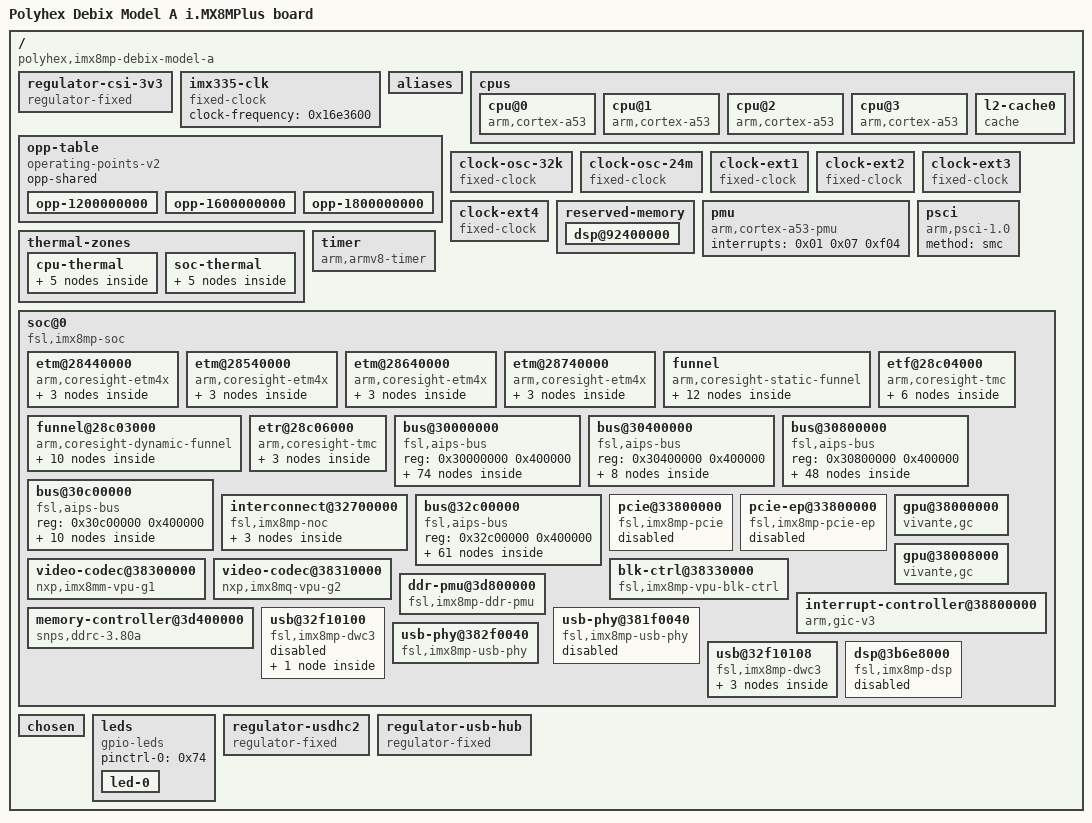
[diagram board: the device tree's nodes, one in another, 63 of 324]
/dts-v1/;

/ {
	interrupt-parent = <0x01>;
	#address-cells = <0x02>;
	#size-cells = <0x02>;
	model = "Polyhex Debix Model A i.MX8MPlus board";
	compatible = "polyhex,imx8mp-debix-model-a\0polyhex,imx8mp-debix\0fsl,imx8mp";

	regulator-csi-3v3 {
		phandle = <0xe7>;
		enable-active-high;
		gpio = <0x2f 0x06 0x00>;
		startup-delay-us = <0xc350>;
		regulator-min-microvolt = <0x325aa0>;
		regulator-max-microvolt = <0x325aa0>;
		regulator-name = "CSI_3V3";
		pinctrl-0 = <0xe3 0xe4>;
		pinctrl-names = "default";
		compatible = "regulator-fixed";
	};

	imx335-clk {
		phandle = <0xe6>;
		clock-frequency = <0x16e3600>;
		#clock-cells = <0x00>;
		compatible = "fixed-clock";
	};

	aliases {
		ethernet0 = "/soc@0/bus@30800000/ethernet@30be0000";
		ethernet1 = "/soc@0/bus@30800000/ethernet@30bf0000";
		gpio0 = "/soc@0/bus@30000000/gpio@30200000";
		gpio1 = "/soc@0/bus@30000000/gpio@30210000";
		gpio2 = "/soc@0/bus@30000000/gpio@30220000";
		gpio3 = "/soc@0/bus@30000000/gpio@30230000";
		gpio4 = "/soc@0/bus@30000000/gpio@30240000";
		i2c0 = "/soc@0/bus@30800000/i2c@30a20000";
		i2c1 = "/soc@0/bus@30800000/i2c@30a30000";
		i2c2 = "/soc@0/bus@30800000/i2c@30a40000";
		i2c3 = "/soc@0/bus@30800000/i2c@30a50000";
		i2c4 = "/soc@0/bus@30800000/i2c@30ad0000";
		i2c5 = "/soc@0/bus@30800000/i2c@30ae0000";
		mmc0 = "/soc@0/bus@30800000/mmc@30b40000";
		mmc1 = "/soc@0/bus@30800000/mmc@30b50000";
		mmc2 = "/soc@0/bus@30800000/mmc@30b60000";
		serial0 = "/soc@0/bus@30800000/spba-bus@30800000/serial@30860000";
		serial1 = "/soc@0/bus@30800000/spba-bus@30800000/serial@30890000";
		serial2 = "/soc@0/bus@30800000/spba-bus@30800000/serial@30880000";
		serial3 = "/soc@0/bus@30800000/serial@30a60000";
		spi0 = "/soc@0/bus@30800000/spi@30bb0000";
	};

	cpus {
		#address-cells = <0x01>;
		#size-cells = <0x00>;

		cpu@0 {
			device_type = "cpu";
			compatible = "arm,cortex-a53";
			reg = <0x00>;
			clock-latency = <0xee6c>;
			clocks = <0x02 0x11f>;
			enable-method = "psci";
			i-cache-size = <0x8000>;
			i-cache-line-size = <0x40>;
			i-cache-sets = <0x100>;
			d-cache-size = <0x8000>;
			d-cache-line-size = <0x40>;
			d-cache-sets = <0x80>;
			next-level-cache = <0x03>;
			nvmem-cells = <0x04>;
			nvmem-cell-names = "speed_grade";
			operating-points-v2 = <0x05>;
			#cooling-cells = <0x02>;
			cpu-supply = <0x06>;
			phandle = <0x09>;
		};

		cpu@1 {
			device_type = "cpu";
			compatible = "arm,cortex-a53";
			reg = <0x01>;
			clock-latency = <0xee6c>;
			clocks = <0x02 0x11f>;
			enable-method = "psci";
			i-cache-size = <0x8000>;
			i-cache-line-size = <0x40>;
			i-cache-sets = <0x100>;
			d-cache-size = <0x8000>;
			d-cache-line-size = <0x40>;
			d-cache-sets = <0x80>;
			next-level-cache = <0x03>;
			operating-points-v2 = <0x05>;
			#cooling-cells = <0x02>;
			cpu-supply = <0x06>;
			phandle = <0x0a>;
		};

		cpu@2 {
			device_type = "cpu";
			compatible = "arm,cortex-a53";
			reg = <0x02>;
			clock-latency = <0xee6c>;
			clocks = <0x02 0x11f>;
			enable-method = "psci";
			i-cache-size = <0x8000>;
			i-cache-line-size = <0x40>;
			i-cache-sets = <0x100>;
			d-cache-size = <0x8000>;
			d-cache-line-size = <0x40>;
			d-cache-sets = <0x80>;
			next-level-cache = <0x03>;
			operating-points-v2 = <0x05>;
			#cooling-cells = <0x02>;
			cpu-supply = <0x06>;
			phandle = <0x0b>;
		};

		cpu@3 {
			device_type = "cpu";
			compatible = "arm,cortex-a53";
			reg = <0x03>;
			clock-latency = <0xee6c>;
			clocks = <0x02 0x11f>;
			enable-method = "psci";
			i-cache-size = <0x8000>;
			i-cache-line-size = <0x40>;
			i-cache-sets = <0x100>;
			d-cache-size = <0x8000>;
			d-cache-line-size = <0x40>;
			d-cache-sets = <0x80>;
			next-level-cache = <0x03>;
			operating-points-v2 = <0x05>;
			#cooling-cells = <0x02>;
			cpu-supply = <0x06>;
			phandle = <0x0c>;
		};

		l2-cache0 {
			compatible = "cache";
			cache-unified;
			cache-level = <0x02>;
			cache-size = <0x80000>;
			cache-line-size = <0x40>;
			cache-sets = <0x200>;
			phandle = <0x03>;
		};
	};

	opp-table {
		compatible = "operating-points-v2";
		opp-shared;
		phandle = <0x05>;

		opp-1200000000 {
			opp-hz = <0x00 0x47868c00>;
			opp-microvolt = <0xcf850>;
			opp-supported-hw = <0x8a0 0x07>;
			clock-latency-ns = <0x249f0>;
			opp-suspend;
		};

		opp-1600000000 {
			opp-hz = <0x00 0x5f5e1000>;
			opp-microvolt = <0xe7ef0>;
			opp-supported-hw = <0xa0 0x07>;
			clock-latency-ns = <0x249f0>;
			opp-suspend;
		};

		opp-1800000000 {
			opp-hz = <0x00 0x6b49d200>;
			opp-microvolt = <0xf4240>;
			opp-supported-hw = <0x20 0x03>;
			clock-latency-ns = <0x249f0>;
			opp-suspend;
		};
	};

	clock-osc-32k {
		compatible = "fixed-clock";
		#clock-cells = <0x00>;
		clock-frequency = <0x8000>;
		clock-output-names = "osc_32k";
		phandle = <0x21>;
	};

	clock-osc-24m {
		compatible = "fixed-clock";
		#clock-cells = <0x00>;
		clock-frequency = <0x16e3600>;
		clock-output-names = "osc_24m";
		phandle = <0x22>;
	};

	clock-ext1 {
		compatible = "fixed-clock";
		#clock-cells = <0x00>;
		clock-frequency = <0x7ed6b40>;
		clock-output-names = "clk_ext1";
		phandle = <0x23>;
	};

	clock-ext2 {
		compatible = "fixed-clock";
		#clock-cells = <0x00>;
		clock-frequency = <0x7ed6b40>;
		clock-output-names = "clk_ext2";
		phandle = <0x24>;
	};

	clock-ext3 {
		compatible = "fixed-clock";
		#clock-cells = <0x00>;
		clock-frequency = <0x7ed6b40>;
		clock-output-names = "clk_ext3";
		phandle = <0x25>;
	};

	clock-ext4 {
		compatible = "fixed-clock";
		#clock-cells = <0x00>;
		clock-frequency = <0x7ed6b40>;
		clock-output-names = "clk_ext4";
		phandle = <0x26>;
	};

	reserved-memory {
		#address-cells = <0x02>;
		#size-cells = <0x02>;
		ranges;

		dsp@92400000 {
			reg = <0x00 0x92400000 0x00 0x2000000>;
			no-map;
			phandle = <0x73>;
		};
	};

	pmu {
		compatible = "arm,cortex-a53-pmu";
		interrupts = <0x01 0x07 0xf04>;
	};

	psci {
		compatible = "arm,psci-1.0";
		method = "smc";
	};

	thermal-zones {

		cpu-thermal {
			polling-delay-passive = <0xfa>;
			polling-delay = <0x7d0>;
			thermal-sensors = <0x07 0x00>;

			trips {

				trip0 {
					temperature = <0x14c08>;
					hysteresis = <0x7d0>;
					type = "passive";
					phandle = <0x08>;
				};

				trip1 {
					temperature = <0x17318>;
					hysteresis = <0x7d0>;
					type = "critical";
					phandle = <0x78>;
				};
			};

			cooling-maps {

				map0 {
					trip = <0x08>;
					cooling-device = <0x09 0xffffffff 0xffffffff 0x0a 0xffffffff 0xffffffff 0x0b 0xffffffff 0xffffffff 0x0c 0xffffffff 0xffffffff>;
				};
			};
		};

		soc-thermal {
			polling-delay-passive = <0xfa>;
			polling-delay = <0x7d0>;
			thermal-sensors = <0x07 0x01>;

			trips {

				trip0 {
					temperature = <0x14c08>;
					hysteresis = <0x7d0>;
					type = "passive";
					phandle = <0x0d>;
				};

				trip1 {
					temperature = <0x17318>;
					hysteresis = <0x7d0>;
					type = "critical";
					phandle = <0x79>;
				};
			};

			cooling-maps {

				map0 {
					trip = <0x0d>;
					cooling-device = <0x09 0xffffffff 0xffffffff 0x0a 0xffffffff 0xffffffff 0x0b 0xffffffff 0xffffffff 0x0c 0xffffffff 0xffffffff>;
				};
			};
		};
	};

	timer {
		compatible = "arm,armv8-timer";
		interrupts = <0x01 0x0d 0xf08 0x01 0x0e 0xf08 0x01 0x0b 0xf08 0x01 0x0a 0xf08>;
		clock-frequency = <0x7a1200>;
		arm,no-tick-in-suspend;
	};

	soc@0 {
		compatible = "fsl,imx8mp-soc\0simple-bus";
		#address-cells = <0x01>;
		#size-cells = <0x01>;
		ranges = <0x00 0x00 0x00 0x3e000000>;
		nvmem-cells = <0x0e>;
		nvmem-cell-names = "soc_unique_id";
		phandle = <0x7a>;

		etm@28440000 {
			compatible = "arm,coresight-etm4x\0arm,primecell";
			reg = <0x28440000 0x1000>;
			cpu = <0x09>;
			clocks = <0x02 0x5d>;
			clock-names = "apb_pclk";
			phandle = <0x7b>;

			out-ports {

				port {

					endpoint {
						remote-endpoint = <0x0f>;
						phandle = <0x13>;
					};
				};
			};
		};

		etm@28540000 {
			compatible = "arm,coresight-etm4x\0arm,primecell";
			reg = <0x28540000 0x1000>;
			cpu = <0x0a>;
			clocks = <0x02 0x5d>;
			clock-names = "apb_pclk";
			phandle = <0x7c>;

			out-ports {

				port {

					endpoint {
						remote-endpoint = <0x10>;
						phandle = <0x14>;
					};
				};
			};
		};

		etm@28640000 {
			compatible = "arm,coresight-etm4x\0arm,primecell";
			reg = <0x28640000 0x1000>;
			cpu = <0x0b>;
			clocks = <0x02 0x5d>;
			clock-names = "apb_pclk";
			phandle = <0x7d>;

			out-ports {

				port {

					endpoint {
						remote-endpoint = <0x11>;
						phandle = <0x15>;
					};
				};
			};
		};

		etm@28740000 {
			compatible = "arm,coresight-etm4x\0arm,primecell";
			reg = <0x28740000 0x1000>;
			cpu = <0x0c>;
			clocks = <0x02 0x5d>;
			clock-names = "apb_pclk";
			phandle = <0x7e>;

			out-ports {

				port {

					endpoint {
						remote-endpoint = <0x12>;
						phandle = <0x16>;
					};
				};
			};
		};

		funnel {
			compatible = "arm,coresight-static-funnel";

			in-ports {
				#address-cells = <0x01>;
				#size-cells = <0x00>;

				port@0 {
					reg = <0x00>;

					endpoint {
						remote-endpoint = <0x13>;
						phandle = <0x0f>;
					};
				};

				port@1 {
					reg = <0x01>;

					endpoint {
						remote-endpoint = <0x14>;
						phandle = <0x10>;
					};
				};

				port@2 {
					reg = <0x02>;

					endpoint {
						remote-endpoint = <0x15>;
						phandle = <0x11>;
					};
				};

				port@3 {
					reg = <0x03>;

					endpoint {
						remote-endpoint = <0x16>;
						phandle = <0x12>;
					};
				};
			};

			out-ports {

				port {

					endpoint {
						remote-endpoint = <0x17>;
						phandle = <0x18>;
					};
				};
			};
		};

		funnel@28c03000 {
			compatible = "arm,coresight-dynamic-funnel\0arm,primecell";
			reg = <0x28c03000 0x1000>;
			clocks = <0x02 0x5d>;
			clock-names = "apb_pclk";

			in-ports {
				#address-cells = <0x01>;
				#size-cells = <0x00>;

				port@0 {
					reg = <0x00>;

					endpoint {
						remote-endpoint = <0x18>;
						phandle = <0x17>;
					};
				};

				port@1 {
					reg = <0x01>;

					endpoint {
						phandle = <0x7f>;
					};
				};

				port@2 {
					reg = <0x02>;

					endpoint {
						phandle = <0x80>;
					};
				};
			};

			out-ports {

				port {

					endpoint {
						remote-endpoint = <0x19>;
						phandle = <0x1a>;
					};
				};
			};
		};

		etf@28c04000 {
			compatible = "arm,coresight-tmc\0arm,primecell";
			reg = <0x28c04000 0x1000>;
			clocks = <0x02 0x5d>;
			clock-names = "apb_pclk";

			in-ports {

				port {

					endpoint {
						remote-endpoint = <0x1a>;
						phandle = <0x19>;
					};
				};
			};

			out-ports {

				port {

					endpoint {
						remote-endpoint = <0x1b>;
						phandle = <0x1c>;
					};
				};
			};
		};

		etr@28c06000 {
			compatible = "arm,coresight-tmc\0arm,primecell";
			reg = <0x28c06000 0x1000>;
			clocks = <0x02 0x5d>;
			clock-names = "apb_pclk";

			in-ports {

				port {

					endpoint {
						remote-endpoint = <0x1c>;
						phandle = <0x1b>;
					};
				};
			};
		};

		bus@30000000 {
			compatible = "fsl,aips-bus\0simple-bus";
			reg = <0x30000000 0x400000>;
			#address-cells = <0x01>;
			#size-cells = <0x01>;
			ranges;
			phandle = <0x81>;

			gpio@30200000 {
				compatible = "fsl,imx8mp-gpio\0fsl,imx35-gpio";
				reg = <0x30200000 0x10000>;
				interrupts = <0x00 0x40 0x04 0x00 0x41 0x04>;
				clocks = <0x02 0xc1>;
				gpio-controller;
				#gpio-cells = <0x02>;
				interrupt-controller;
				#interrupt-cells = <0x02>;
				gpio-ranges = <0x1d 0x00 0x05 0x1e>;
				phandle = <0x2f>;
			};

			gpio@30210000 {
				compatible = "fsl,imx8mp-gpio\0fsl,imx35-gpio";
				reg = <0x30210000 0x10000>;
				interrupts = <0x00 0x42 0x04 0x00 0x43 0x04>;
				clocks = <0x02 0xc2>;
				gpio-controller;
				#gpio-cells = <0x02>;
				interrupt-controller;
				#interrupt-cells = <0x02>;
				gpio-ranges = <0x1d 0x00 0x23 0x15>;
				phandle = <0x32>;
			};

			gpio@30220000 {
				compatible = "fsl,imx8mp-gpio\0fsl,imx35-gpio";
				reg = <0x30220000 0x10000>;
				interrupts = <0x00 0x44 0x04 0x00 0x45 0x04>;
				clocks = <0x02 0xc3>;
				gpio-controller;
				#gpio-cells = <0x02>;
				interrupt-controller;
				#interrupt-cells = <0x02>;
				gpio-ranges = <0x1d 0x00 0x38 0x1a 0x1d 0x1a 0x90 0x04>;
				phandle = <0x75>;
			};

			gpio@30230000 {
				compatible = "fsl,imx8mp-gpio\0fsl,imx35-gpio";
				reg = <0x30230000 0x10000>;
				interrupts = <0x00 0x46 0x04 0x00 0x47 0x04>;
				clocks = <0x02 0xc4>;
				gpio-controller;
				#gpio-cells = <0x02>;
				interrupt-controller;
				#interrupt-cells = <0x02>;
				gpio-ranges = <0x1d 0x00 0x52 0x20>;
				phandle = <0x42>;
			};

			gpio@30240000 {
				compatible = "fsl,imx8mp-gpio\0fsl,imx35-gpio";
				reg = <0x30240000 0x10000>;
				interrupts = <0x00 0x48 0x04 0x00 0x49 0x04>;
				clocks = <0x02 0xc5>;
				gpio-controller;
				#gpio-cells = <0x02>;
				interrupt-controller;
				#interrupt-cells = <0x02>;
				gpio-ranges = <0x1d 0x00 0x72 0x1e>;
				phandle = <0x82>;
			};

			tmu@30260000 {
				compatible = "fsl,imx8mp-tmu";
				reg = <0x30260000 0x10000>;
				clocks = <0x02 0x119>;
				nvmem-cells = <0x1e>;
				nvmem-cell-names = "calib";
				#thermal-sensor-cells = <0x01>;
				phandle = <0x07>;
			};

			watchdog@30280000 {
				compatible = "fsl,imx8mp-wdt\0fsl,imx21-wdt";
				reg = <0x30280000 0x10000>;
				interrupts = <0x00 0x4e 0x04>;
				clocks = <0x02 0x103>;
				status = "okay";
				pinctrl-names = "default";
				pinctrl-0 = <0x1f>;
				fsl,ext-reset-output;
				phandle = <0x83>;
			};

			watchdog@30290000 {
				compatible = "fsl,imx8mp-wdt\0fsl,imx21-wdt";
				reg = <0x30290000 0x10000>;
				interrupts = <0x00 0x4f 0x04>;
				clocks = <0x02 0x104>;
				status = "disabled";
				phandle = <0x84>;
			};

			watchdog@302a0000 {
				compatible = "fsl,imx8mp-wdt\0fsl,imx21-wdt";
				reg = <0x302a0000 0x10000>;
				interrupts = <0x00 0x0a 0x04>;
				clocks = <0x02 0x105>;
				status = "disabled";
				phandle = <0x85>;
			};

			timer@302d0000 {
				compatible = "fsl,imx8mp-gpt\0fsl,imx6dl-gpt";
				reg = <0x302d0000 0x10000>;
				interrupts = <0x00 0x37 0x04>;
				clocks = <0x02 0xc6 0x02 0x9b>;
				clock-names = "ipg\0per";
				phandle = <0x86>;
			};

			timer@302e0000 {
				compatible = "fsl,imx8mp-gpt\0fsl,imx6dl-gpt";
				reg = <0x302e0000 0x10000>;
				interrupts = <0x00 0x36 0x04>;
				clocks = <0x02 0xc7 0x02 0x9c>;
				clock-names = "ipg\0per";
				phandle = <0x87>;
			};

			timer@302f0000 {
				compatible = "fsl,imx8mp-gpt\0fsl,imx6dl-gpt";
				reg = <0x302f0000 0x10000>;
				interrupts = <0x00 0x35 0x04>;
				clocks = <0x02 0xc8 0x02 0x9d>;
				clock-names = "ipg\0per";
				phandle = <0x88>;
			};

			pinctrl@30330000 {
				compatible = "fsl,imx8mp-iomuxc";
				reg = <0x30330000 0x10000>;
				phandle = <0x1d>;

				i2c2grp {
					phandle = <0xe5>;
					fsl,pins = <0x208 0x468 0x5ac 0x00 0x02 0x400001c2 0x20c 0x46c 0x5b0 0x00 0x02 0x400001c2>;
				};

				csi0_rst_grp {
					phandle = <0xe4>;
					fsl,pins = <0x2c 0x28c 0x00 0x00 0x00 0x19>;
				};

				csi0_pwn_grp {
					phandle = <0xe3>;
					fsl,pins = <0x50 0x2b0 0x00 0x00 0x00 0x19>;
				};

				eqosgrp {
					fsl,pins = <0x54 0x2b4 0x00 0x00 0x00 0x03 0x58 0x2b8 0x590 0x00 0x01 0x03 0x7c 0x2dc 0x00 0x00 0x00 0x91 0x80 0x2e0 0x00 0x00 0x00 0x91 0x84 0x2e4 0x00 0x00 0x00 0x91 0x88 0x2e8 0x00 0x00 0x00 0x91 0x78 0x2d8 0x00 0x00 0x00 0x91 0x74 0x2d4 0x00 0x00 0x00 0x91 0x68 0x2c8 0x00 0x00 0x00 0x1f 0x64 0x2c4 0x00 0x00 0x00 0x1f 0x60 0x2c0 0x00 0x00 0x00 0x1f 0x5c 0x2bc 0x00 0x00 0x00 0x1f 0x6c 0x2cc 0x00 0x00 0x00 0x1f 0x70 0x2d0 0x00 0x00 0x00 0x1f 0x148 0x3a8 0x00 0x04 0x00 0x1f 0x14c 0x3ac 0x00 0x04 0x00 0x1f 0x190 0x3f0 0x00 0x05 0x00 0x19>;
					phandle = <0x40>;
				};

				gpioledgrp {
					fsl,pins = <0x120 0x380 0x00 0x05 0x00 0x19>;
					phandle = <0x74>;
				};

				hdmigrp {
					fsl,pins = <0x240 0x4a0 0x00 0x00 0x00 0x1c3 0x244 0x4a4 0x00 0x00 0x00 0x1c3 0x24c 0x4ac 0x00 0x00 0x00 0x19 0x248 0x4a8 0x00 0x00 0x00 0x19>;
					phandle = <0x63>;
				};

				i2c1grp {
					fsl,pins = <0x200 0x460 0x5a4 0x00 0x02 0x400001c2 0x204 0x464 0x5a8 0x00 0x02 0x400001c2>;
					phandle = <0x2d>;
				};

				i2c3grp {
					fsl,pins = <0x210 0x470 0x5b4 0x00 0x04 0x400001c2 0x214 0x474 0x5b8 0x00 0x04 0x400001c2>;
					phandle = <0x30>;
				};

				i2c4grp {
					fsl,pins = <0x218 0x478 0x5bc 0x00 0x05 0x400001c3 0x21c 0x47c 0x5c0 0x00 0x05 0x400001c3>;
					phandle = <0x31>;
				};

				i2c6grp {
					fsl,pins = <0x12c 0x38c 0x5cc 0x03 0x01 0x400001c3 0x130 0x390 0x5d0 0x03 0x01 0x400001c3>;
					phandle = <0x35>;
				};

				pmicirqgrp {
					fsl,pins = <0x20 0x280 0x00 0x00 0x00 0x41>;
					phandle = <0x2e>;
				};

				regusdhc2vmmcgrp {
					fsl,pins = <0xd8 0x338 0x00 0x05 0x00 0x41>;
					phandle = <0x76>;
				};

				regusbhubgrp {
					fsl,pins = <0x1b0 0x410 0x00 0x05 0x00 0x19>;
					phandle = <0x77>;
				};

				rtcintgrp {
					fsl,pins = <0xb8 0x318 0x00 0x05 0x00 0x140>;
					phandle = <0x33>;
				};

				uart2grp {
					fsl,pins = <0x228 0x488 0x5f0 0x00 0x06 0x14f 0x22c 0x48c 0x00 0x00 0x00 0x14f>;
					phandle = <0x2b>;
				};

				uart3grp {
					fsl,pins = <0x230 0x490 0x5f8 0x00 0x06 0x49 0x234 0x494 0x00 0x00 0x00 0x49>;
					phandle = <0x2a>;
				};

				uart4grp {
					fsl,pins = <0x238 0x498 0x600 0x00 0x08 0x49 0x23c 0x49c 0x00 0x00 0x00 0x49>;
					phandle = <0x34>;
				};

				usb1grp {
					fsl,pins = <0x4c 0x2ac 0x00 0x01 0x00 0x10 0x1ac 0x40c 0x00 0x05 0x00 0x19>;
					phandle = <0x6e>;
				};

				usdhc2grp {
					fsl,pins = <0xc0 0x320 0x00 0x00 0x00 0x190 0xc4 0x324 0x00 0x00 0x00 0x1d0 0xc8 0x328 0x00 0x00 0x00 0x1d0 0xcc 0x32c 0x00 0x00 0x00 0x1d0 0xd0 0x330 0x00 0x00 0x00 0x1d0 0xd4 0x334 0x00 0x00 0x00 0x1d0>;
					phandle = <0x36>;
				};

				usdhc2-100mhzgrp {
					fsl,pins = <0xc0 0x320 0x00 0x00 0x00 0x194 0xc4 0x324 0x00 0x00 0x00 0x1d4 0xc8 0x328 0x00 0x00 0x00 0x1d4 0xcc 0x32c 0x00 0x00 0x00 0x1d4 0xd0 0x330 0x00 0x00 0x00 0x1d4 0xd4 0x334 0x00 0x00 0x00 0x1d4>;
					phandle = <0x38>;
				};

				usdhc2-200mhzgrp {
					fsl,pins = <0xc0 0x320 0x00 0x00 0x00 0x196 0xc4 0x324 0x00 0x00 0x00 0x1d6 0xc8 0x328 0x00 0x00 0x00 0x1d6 0xcc 0x32c 0x00 0x00 0x00 0x1d6 0xd0 0x330 0x00 0x00 0x00 0x1d6 0xd4 0x334 0x00 0x00 0x00 0x1d6>;
					phandle = <0x39>;
				};

				usdhc2gpiogrp {
					fsl,pins = <0xbc 0x31c 0x00 0x05 0x00 0x1c4>;
					phandle = <0x37>;
				};

				usdhc3grp {
					fsl,pins = <0x124 0x384 0x604 0x02 0x01 0x190 0x128 0x388 0x60c 0x02 0x01 0x1d0 0x108 0x368 0x610 0x02 0x01 0x1d0 0x10c 0x36c 0x614 0x02 0x01 0x1d0 0x110 0x370 0x618 0x02 0x01 0x1d0 0x114 0x374 0x61c 0x02 0x01 0x1d0 0x11c 0x37c 0x620 0x02 0x01 0x1d0 0xec 0x34c 0x624 0x02 0x01 0x1d0 0xf0 0x350 0x628 0x02 0x01 0x1d0 0xf4 0x354 0x62c 0x02 0x01 0x1d0 0xe8 0x348 0x630 0x02 0x01 0x190>;
					phandle = <0x3b>;
				};

				usdhc3-100mhzgrp {
					fsl,pins = <0x124 0x384 0x604 0x02 0x01 0x194 0x128 0x388 0x60c 0x02 0x01 0x1d4 0x108 0x368 0x610 0x02 0x01 0x1d4 0x10c 0x36c 0x614 0x02 0x01 0x1d4 0x110 0x370 0x618 0x02 0x01 0x1d4 0x114 0x374 0x61c 0x02 0x01 0x1d4 0x11c 0x37c 0x620 0x02 0x01 0x1d4 0xec 0x34c 0x624 0x02 0x01 0x1d4 0xf0 0x350 0x628 0x02 0x01 0x1d4 0xf4 0x354 0x62c 0x02 0x01 0x1d4 0xe8 0x348 0x630 0x02 0x01 0x194>;
					phandle = <0x3c>;
				};

				usdhc3-200mhzgrp {
					fsl,pins = <0x124 0x384 0x604 0x02 0x01 0x196 0x128 0x388 0x60c 0x02 0x01 0x1d6 0x108 0x368 0x610 0x02 0x01 0x1d6 0x10c 0x36c 0x614 0x02 0x01 0x1d6 0x110 0x370 0x618 0x02 0x01 0x1d6 0x114 0x374 0x61c 0x02 0x01 0x1d6 0x11c 0x37c 0x620 0x02 0x01 0x1d6 0xec 0x34c 0x624 0x02 0x01 0x1d6 0xf0 0x350 0x628 0x02 0x01 0x1d6 0xf4 0x354 0x62c 0x02 0x01 0x1d6 0xe8 0x348 0x630 0x02 0x01 0x196>;
					phandle = <0x3d>;
				};

				wdoggrp {
					fsl,pins = <0x1c 0x27c 0x00 0x01 0x00 0xc6>;
					phandle = <0x1f>;
				};
			};

			syscon@30340000 {
				compatible = "fsl,imx8mp-iomuxc-gpr\0syscon";
				reg = <0x30340000 0x10000>;
				phandle = <0x2c>;
			};

			efuse@30350000 {
				compatible = "fsl,imx8mp-ocotp\0fsl,imx8mm-ocotp\0syscon";
				reg = <0x30350000 0x10000>;
				clocks = <0x02 0xd6>;
				#address-cells = <0x01>;
				#size-cells = <0x01>;
				phandle = <0x89>;

				unique-id@8 {
					reg = <0x08 0x08>;
					phandle = <0x0e>;
				};

				speed-grade@10 {
					reg = <0x10 0x04>;
					phandle = <0x04>;
				};

				mac-address@90 {
					reg = <0x90 0x06>;
					phandle = <0x3e>;
				};

				mac-address@96 {
					reg = <0x96 0x06>;
					phandle = <0x3f>;
				};

				calib@264 {
					reg = <0x264 0x10>;
					phandle = <0x1e>;
				};
			};

			clock-controller@30360000 {
				compatible = "fsl,imx8mp-anatop\0fsl,imx8mm-anatop";
				reg = <0x30360000 0x10000>;
				#clock-cells = <0x01>;
				phandle = <0x8a>;
			};

			snvs@30370000 {
				compatible = "fsl,sec-v4.0-mon\0syscon\0simple-mfd";
				reg = <0x30370000 0x10000>;
				phandle = <0x20>;

				snvs-rtc-lp {
					compatible = "fsl,sec-v4.0-mon-rtc-lp";
					regmap = <0x20>;
					offset = <0x34>;
					interrupts = <0x00 0x13 0x04 0x00 0x14 0x04>;
					clocks = <0x02 0xf9>;
					clock-names = "snvs-rtc";
					phandle = <0x8b>;
				};

				snvs-powerkey {
					compatible = "fsl,sec-v4.0-pwrkey";
					regmap = <0x20>;
					interrupts = <0x00 0x04 0x04>;
					clocks = <0x02 0xf9>;
					clock-names = "snvs-pwrkey";
					linux,keycode = <0x74>;
					wakeup-source;
					status = "okay";
					phandle = <0x8c>;
				};

				snvs-lpgpr {
					compatible = "fsl,imx8mp-snvs-lpgpr\0fsl,imx7d-snvs-lpgpr";
					phandle = <0x8d>;
				};
			};

			clock-controller@30380000 {
				compatible = "fsl,imx8mp-ccm";
				reg = <0x30380000 0x10000>;
				#clock-cells = <0x01>;
				clocks = <0x21 0x22 0x23 0x24 0x25 0x26>;
				clock-names = "osc_32k\0osc_24m\0clk_ext1\0clk_ext2\0clk_ext3\0clk_ext4";
				assigned-clocks = <0x02 0x42 0x02 0x120 0x02 0x67 0x02 0x68 0x02 0x94>;
				assigned-clock-parents = <0x02 0x38 0x02 0x2c 0x02 0x41 0x02 0x38 0x02 0x40>;
				assigned-clock-rates = <0x00 0x00 0x3b9aca00 0x2faf0800 0x1dcd6500>;
				phandle = <0x02>;
			};

			reset-controller@30390000 {
				compatible = "fsl,imx8mp-src\0syscon";
				reg = <0x30390000 0x10000>;
				interrupts = <0x00 0x59 0x04>;
				#reset-cells = <0x01>;
				phandle = <0x55>;
			};

			gpc@303a0000 {
				compatible = "fsl,imx8mp-gpc";
				reg = <0x303a0000 0x1000>;
				interrupt-parent = <0x01>;
				interrupts = <0x00 0x57 0x04>;
				interrupt-controller;
				#interrupt-cells = <0x03>;
				phandle = <0x8e>;

				pgc {
					#address-cells = <0x01>;
					#size-cells = <0x00>;

					power-domain@0 {
						#power-domain-cells = <0x00>;
						reg = <0x00>;
						phandle = <0x50>;
					};

					power-domain@1 {
						#power-domain-cells = <0x00>;
						reg = <0x01>;
						phandle = <0x5a>;
					};

					power-domain@2 {
						#power-domain-cells = <0x00>;
						reg = <0x02>;
						phandle = <0x58>;
					};

					power-domain@3 {
						#power-domain-cells = <0x00>;
						reg = <0x03>;
						phandle = <0x59>;
					};

					power-domain@5 {
						#power-domain-cells = <0x00>;
						reg = <0x05>;
						clocks = <0x02 0x11c 0x02 0x136>;
						phandle = <0x45>;
					};

					power-domain@6 {
						#power-domain-cells = <0x00>;
						reg = <0x06>;
						clocks = <0x02 0xf7>;
						power-domains = <0x27>;
						phandle = <0x67>;
					};

					power-domain@7 {
						#power-domain-cells = <0x00>;
						reg = <0x07>;
						clocks = <0x02 0x107 0x02 0x66>;
						assigned-clocks = <0x02 0x65 0x02 0x66>;
						assigned-clock-parents = <0x02 0x38 0x02 0x38>;
						assigned-clock-rates = <0x2faf0800 0x17d78400>;
						phandle = <0x27>;
					};

					power-domain@9 {
						#power-domain-cells = <0x00>;
						reg = <0x09>;
						clocks = <0x02 0xf8 0x02 0x134>;
						power-domains = <0x27>;
						phandle = <0x66>;
					};

					power-domain@10 {
						#power-domain-cells = <0x00>;
						reg = <0x0a>;
						clocks = <0x02 0x10e 0x02 0x10d>;
						phandle = <0x4f>;
					};

					power-domains@14 {
						#power-domain-cells = <0x00>;
						reg = <0x0e>;
						clocks = <0x02 0x116 0x02 0x63>;
						assigned-clocks = <0x02 0x64 0x02 0x63>;
						assigned-clock-parents = <0x02 0x40 0x02 0x33>;
						assigned-clock-rates = <0x1dcd6500 0x7ed6b40>;
						phandle = <0x5b>;
					};

					power-domains@15 {
						#power-domain-cells = <0x00>;
						reg = <0x0f>;
						phandle = <0x5c>;
					};

					power-domain@16 {
						#power-domain-cells = <0x00>;
						reg = <0x10>;
						phandle = <0x51>;
					};

					power-domain@17 {
						#power-domain-cells = <0x00>;
						reg = <0x11>;
						clocks = <0x02 0x137 0x02 0x10c>;
						assigned-clocks = <0x02 0x137>;
						assigned-clock-parents = <0x02 0x40>;
						assigned-clock-rates = <0x1dcd6500>;
						phandle = <0x57>;
					};

					power-domain@18 {
						#power-domain-cells = <0x00>;
						reg = <0x12>;
						clocks = <0x02 0x114>;
						phandle = <0x52>;
					};

					power-domain@19 {
						#power-domain-cells = <0x00>;
						reg = <0x08>;
						clocks = <0x02 0x11a>;
						phandle = <0x28>;
					};

					power-domain@20 {
						#power-domain-cells = <0x00>;
						power-domains = <0x28>;
						reg = <0x0b>;
						clocks = <0x02 0x106>;
						phandle = <0x69>;
					};

					power-domain@21 {
						#power-domain-cells = <0x00>;
						power-domains = <0x28>;
						reg = <0x0c>;
						clocks = <0x02 0x10a>;
						phandle = <0x6a>;
					};

					power-domain@22 {
						#power-domain-cells = <0x00>;
						power-domains = <0x28>;
						reg = <0x0d>;
						clocks = <0x02 0x109>;
						phandle = <0x6b>;
					};

					power-domain@24 {
						#power-domain-cells = <0x00>;
						reg = <0x04>;
						clocks = <0x02 0x69 0x02 0x6a 0x02 0x10b>;
						phandle = <0x8f>;
					};
				};
			};
		};

		bus@30400000 {
			compatible = "fsl,aips-bus\0simple-bus";
			reg = <0x30400000 0x400000>;
			#address-cells = <0x01>;
			#size-cells = <0x01>;
			ranges;
			phandle = <0x90>;

			pwm@30660000 {
				compatible = "fsl,imx8mp-pwm\0fsl,imx27-pwm";
				reg = <0x30660000 0x10000>;
				interrupts = <0x00 0x51 0x04>;
				clocks = <0x02 0xdc 0x02 0xdc>;
				clock-names = "ipg\0per";
				#pwm-cells = <0x03>;
				status = "disabled";
				phandle = <0x91>;
			};

			pwm@30670000 {
				compatible = "fsl,imx8mp-pwm\0fsl,imx27-pwm";
				reg = <0x30670000 0x10000>;
				interrupts = <0x00 0x52 0x04>;
				clocks = <0x02 0xdd 0x02 0xdd>;
				clock-names = "ipg\0per";
				#pwm-cells = <0x03>;
				status = "disabled";
				phandle = <0x92>;
			};

			pwm@30680000 {
				compatible = "fsl,imx8mp-pwm\0fsl,imx27-pwm";
				reg = <0x30680000 0x10000>;
				interrupts = <0x00 0x53 0x04>;
				clocks = <0x02 0xde 0x02 0xde>;
				clock-names = "ipg\0per";
				#pwm-cells = <0x03>;
				status = "disabled";
				phandle = <0x93>;
			};

			pwm@30690000 {
				compatible = "fsl,imx8mp-pwm\0fsl,imx27-pwm";
				reg = <0x30690000 0x10000>;
				interrupts = <0x00 0x54 0x04>;
				clocks = <0x02 0xdf 0x02 0xdf>;
				clock-names = "ipg\0per";
				#pwm-cells = <0x03>;
				status = "disabled";
				phandle = <0x94>;
			};

			timer@306a0000 {
				compatible = "nxp,sysctr-timer";
				reg = <0x306a0000 0x20000>;
				interrupts = <0x00 0x2f 0x04>;
				clocks = <0x22>;
				clock-names = "per";
				phandle = <0x95>;
			};

			timer@306e0000 {
				compatible = "fsl,imx8mp-gpt\0fsl,imx6dl-gpt";
				reg = <0x306e0000 0x10000>;
				interrupts = <0x00 0x33 0x04>;
				clocks = <0x02 0xcb 0x02 0xa0>;
				clock-names = "ipg\0per";
				phandle = <0x96>;
			};

			timer@306f0000 {
				compatible = "fsl,imx8mp-gpt\0fsl,imx6dl-gpt";
				reg = <0x306f0000 0x10000>;
				interrupts = <0x00 0x33 0x04>;
				clocks = <0x02 0xca 0x02 0x9f>;
				clock-names = "ipg\0per";
				phandle = <0x97>;
			};

			timer@30700000 {
				compatible = "fsl,imx8mp-gpt\0fsl,imx6dl-gpt";
				reg = <0x30700000 0x10000>;
				interrupts = <0x00 0x34 0x04>;
				clocks = <0x02 0xc9 0x02 0x9e>;
				clock-names = "ipg\0per";
				phandle = <0x98>;
			};
		};

		bus@30800000 {
			compatible = "fsl,aips-bus\0simple-bus";
			reg = <0x30800000 0x400000>;
			#address-cells = <0x01>;
			#size-cells = <0x01>;
			ranges;
			phandle = <0x99>;

			spba-bus@30800000 {
				compatible = "fsl,spba-bus\0simple-bus";
				reg = <0x30800000 0x100000>;
				#address-cells = <0x01>;
				#size-cells = <0x01>;
				ranges;

				spi@30820000 {
					#address-cells = <0x01>;
					#size-cells = <0x00>;
					compatible = "fsl,imx8mp-ecspi\0fsl,imx6ul-ecspi";
					reg = <0x30820000 0x10000>;
					interrupts = <0x00 0x1f 0x04>;
					clocks = <0x02 0xbd 0x02 0xbd>;
					clock-names = "ipg\0per";
					assigned-clock-rates = <0x4c4b400>;
					assigned-clocks = <0x02 0x95>;
					assigned-clock-parents = <0x02 0x38>;
					dmas = <0x29 0x00 0x07 0x01 0x29 0x01 0x07 0x02>;
					dma-names = "rx\0tx";
					status = "disabled";
					phandle = <0x9a>;
				};

				spi@30830000 {
					#address-cells = <0x01>;
					#size-cells = <0x00>;
					compatible = "fsl,imx8mp-ecspi\0fsl,imx6ul-ecspi";
					reg = <0x30830000 0x10000>;
					interrupts = <0x00 0x20 0x04>;
					clocks = <0x02 0xbe 0x02 0xbe>;
					clock-names = "ipg\0per";
					assigned-clock-rates = <0x4c4b400>;
					assigned-clocks = <0x02 0x96>;
					assigned-clock-parents = <0x02 0x38>;
					dmas = <0x29 0x02 0x07 0x01 0x29 0x03 0x07 0x02>;
					dma-names = "rx\0tx";
					status = "disabled";
					phandle = <0x9b>;
				};

				spi@30840000 {
					#address-cells = <0x01>;
					#size-cells = <0x00>;
					compatible = "fsl,imx8mp-ecspi\0fsl,imx6ul-ecspi";
					reg = <0x30840000 0x10000>;
					interrupts = <0x00 0x21 0x04>;
					clocks = <0x02 0xbf 0x02 0xbf>;
					clock-names = "ipg\0per";
					assigned-clock-rates = <0x4c4b400>;
					assigned-clocks = <0x02 0xb3>;
					assigned-clock-parents = <0x02 0x38>;
					dmas = <0x29 0x04 0x07 0x01 0x29 0x05 0x07 0x02>;
					dma-names = "rx\0tx";
					status = "disabled";
					phandle = <0x9c>;
				};

				serial@30860000 {
					compatible = "fsl,imx8mp-uart\0fsl,imx6q-uart";
					reg = <0x30860000 0x10000>;
					interrupts = <0x00 0x1a 0x04>;
					clocks = <0x02 0xfb 0x02 0xfb>;
					clock-names = "ipg\0per";
					dmas = <0x29 0x16 0x04 0x00 0x29 0x17 0x04 0x00>;
					dma-names = "rx\0tx";
					status = "disabled";
					phandle = <0x9d>;
				};

				serial@30880000 {
					compatible = "fsl,imx8mp-uart\0fsl,imx6q-uart";
					reg = <0x30880000 0x10000>;
					interrupts = <0x00 0x1c 0x04>;
					clocks = <0x02 0xfd 0x02 0xfd>;
					clock-names = "ipg\0per";
					dmas = <0x29 0x1a 0x04 0x00 0x29 0x1b 0x04 0x00>;
					dma-names = "rx\0tx";
					status = "okay";
					pinctrl-names = "default";
					pinctrl-0 = <0x2a>;
					phandle = <0x9e>;
				};

				serial@30890000 {
					compatible = "fsl,imx8mp-uart\0fsl,imx6q-uart";
					reg = <0x30890000 0x10000>;
					interrupts = <0x00 0x1b 0x04>;
					clocks = <0x02 0xfc 0x02 0xfc>;
					clock-names = "ipg\0per";
					dmas = <0x29 0x18 0x04 0x00 0x29 0x19 0x04 0x00>;
					dma-names = "rx\0tx";
					status = "okay";
					pinctrl-names = "default";
					pinctrl-0 = <0x2b>;
					phandle = <0x9f>;
				};

				can@308c0000 {
					compatible = "fsl,imx8mp-flexcan";
					reg = <0x308c0000 0x10000>;
					interrupts = <0x00 0x8e 0x04>;
					clocks = <0x02 0x6e 0x02 0xe9>;
					clock-names = "ipg\0per";
					assigned-clocks = <0x02 0x74>;
					assigned-clock-parents = <0x02 0x30>;
					assigned-clock-rates = <0x2625a00>;
					fsl,clk-source = [00];
					fsl,stop-mode = <0x2c 0x10 0x04>;
					status = "disabled";
					phandle = <0xa0>;
				};

				can@308d0000 {
					compatible = "fsl,imx8mp-flexcan";
					reg = <0x308d0000 0x10000>;
					interrupts = <0x00 0x90 0x04>;
					clocks = <0x02 0x6e 0x02 0xea>;
					clock-names = "ipg\0per";
					assigned-clocks = <0x02 0x75>;
					assigned-clock-parents = <0x02 0x30>;
					assigned-clock-rates = <0x2625a00>;
					fsl,clk-source = [00];
					fsl,stop-mode = <0x2c 0x10 0x05>;
					status = "disabled";
					phandle = <0xa1>;
				};
			};

			crypto@30900000 {
				compatible = "fsl,sec-v4.0";
				#address-cells = <0x01>;
				#size-cells = <0x01>;
				reg = <0x30900000 0x40000>;
				ranges = <0x00 0x30900000 0x40000>;
				interrupts = <0x00 0x5b 0x04>;
				clocks = <0x02 0x6b 0x02 0x6e>;
				clock-names = "aclk\0ipg";
				phandle = <0xa2>;

				jr@1000 {
					compatible = "fsl,sec-v4.0-job-ring";
					reg = <0x1000 0x1000>;
					interrupts = <0x00 0x69 0x04>;
					status = "disabled";
					phandle = <0xa3>;
				};

				jr@2000 {
					compatible = "fsl,sec-v4.0-job-ring";
					reg = <0x2000 0x1000>;
					interrupts = <0x00 0x6a 0x04>;
					phandle = <0xa4>;
				};

				jr@3000 {
					compatible = "fsl,sec-v4.0-job-ring";
					reg = <0x3000 0x1000>;
					interrupts = <0x00 0x72 0x04>;
					phandle = <0xa5>;
				};
			};

			i2c@30a20000 {
				compatible = "fsl,imx8mp-i2c\0fsl,imx21-i2c";
				#address-cells = <0x01>;
				#size-cells = <0x00>;
				reg = <0x30a20000 0x10000>;
				interrupts = <0x00 0x23 0x04>;
				clocks = <0x02 0xcd>;
				status = "okay";
				clock-frequency = <0x61a80>;
				pinctrl-names = "default";
				pinctrl-0 = <0x2d>;
				phandle = <0xa6>;

				pmic@25 {
					compatible = "nxp,pca9450c";
					reg = <0x25>;
					pinctrl-names = "default";
					pinctrl-0 = <0x2e>;
					interrupt-parent = <0x2f>;
					interrupts = <0x03 0x01>;

					regulators {

						BUCK1 {
							regulator-name = "BUCK1";
							regulator-min-microvolt = <0x927c0>;
							regulator-max-microvolt = <0x2160ec>;
							regulator-boot-on;
							regulator-always-on;
							regulator-ramp-delay = <0xc35>;
							phandle = <0xa7>;
						};

						BUCK2 {
							regulator-name = "BUCK2";
							regulator-min-microvolt = <0x927c0>;
							regulator-max-microvolt = <0x2160ec>;
							regulator-boot-on;
							regulator-always-on;
							regulator-ramp-delay = <0xc35>;
							nxp,dvs-run-voltage = <0xe7ef0>;
							nxp,dvs-standby-voltage = <0xcf850>;
							phandle = <0x06>;
						};

						BUCK4 {
							regulator-name = "BUCK4";
							regulator-min-microvolt = <0x927c0>;
							regulator-max-microvolt = <0x33e140>;
							regulator-boot-on;
							regulator-always-on;
							phandle = <0xa8>;
						};

						BUCK5 {
							regulator-name = "BUCK5";
							regulator-min-microvolt = <0x927c0>;
							regulator-max-microvolt = <0x33e140>;
							regulator-boot-on;
							regulator-always-on;
							phandle = <0xa9>;
						};

						BUCK6 {
							regulator-name = "BUCK6";
							regulator-min-microvolt = <0x927c0>;
							regulator-max-microvolt = <0x33e140>;
							regulator-boot-on;
							regulator-always-on;
							phandle = <0xaa>;
						};

						LDO1 {
							regulator-name = "LDO1";
							regulator-min-microvolt = <0x186a00>;
							regulator-max-microvolt = <0x325aa0>;
							regulator-boot-on;
							regulator-always-on;
							phandle = <0xab>;
						};

						LDO2 {
							regulator-name = "LDO2";
							regulator-min-microvolt = "\0\f5";
							regulator-max-microvolt = <0x118c30>;
							regulator-boot-on;
							regulator-always-on;
							phandle = <0xac>;
						};

						LDO3 {
							regulator-name = "LDO3";
							regulator-min-microvolt = "\0\f5";
							regulator-max-microvolt = <0x325aa0>;
							regulator-boot-on;
							regulator-always-on;
							phandle = <0xad>;
						};

						LDO4 {
							regulator-name = "LDO4";
							regulator-min-microvolt = "\0\f5";
							regulator-max-microvolt = <0x325aa0>;
							regulator-boot-on;
							regulator-always-on;
							phandle = <0xae>;
						};

						LDO5 {
							regulator-name = "LDO5";
							regulator-min-microvolt = <0x1b7740>;
							regulator-max-microvolt = <0x325aa0>;
							regulator-boot-on;
							regulator-always-on;
							phandle = <0xaf>;
						};
					};
				};
			};

			i2c@30a30000 {
				pinctrl-0 = <0xe5>;
				pinctrl-names = "default";
				clock-frequency = <0x186a0>;
				compatible = "fsl,imx8mp-i2c\0fsl,imx21-i2c";
				#address-cells = <0x01>;
				#size-cells = <0x00>;
				reg = <0x30a30000 0x10000>;
				interrupts = <0x00 0x24 0x04>;
				clocks = <0x02 0xce>;
				status = "okay";
				phandle = <0xb0>;

				camera@1a {
					orientation = <0x02>;
					rotation = <0x00>;
					DVDD-supply = <0xe7>;
					IOVDD-supply = <0xe7>;
					AVDD-supply = <0xe7>;
					clock-names = "inclk";
					clocks = <0xe6>;
					reg = <0x1a>;
					compatible = "sony,imx335";

					port {

						endpoint {
							phandle = <0xe9>;
							link-frequencies = <0x00 0x1b2e0200>;
							clock-noncontinuous;
							data-lanes = <0x01 0x02 0x03 0x04>;
							remote-endpoint = <0xe8>;
						};
					};
				};
			};

			i2c@30a40000 {
				compatible = "fsl,imx8mp-i2c\0fsl,imx21-i2c";
				#address-cells = <0x01>;
				#size-cells = <0x00>;
				reg = <0x30a40000 0x10000>;
				interrupts = <0x00 0x25 0x04>;
				clocks = <0x02 0xcf>;
				status = "okay";
				clock-frequency = <0x61a80>;
				pinctrl-names = "default";
				pinctrl-0 = <0x30>;
				phandle = <0xb1>;
			};

			i2c@30a50000 {
				compatible = "fsl,imx8mp-i2c\0fsl,imx21-i2c";
				#address-cells = <0x01>;
				#size-cells = <0x00>;
				reg = <0x30a50000 0x10000>;
				interrupts = <0x00 0x26 0x04>;
				clocks = <0x02 0xd0>;
				status = "okay";
				clock-frequency = <0x186a0>;
				pinctrl-names = "default";
				pinctrl-0 = <0x31>;
				phandle = <0xb2>;

				eeprom@50 {
					compatible = "atmel,24c02";
					reg = <0x50>;
					pagesize = <0x10>;
				};

				rtc@51 {
					compatible = "haoyu,hym8563";
					reg = <0x51>;
					#clock-cells = <0x00>;
					clock-output-names = "xin32k";
					interrupt-parent = <0x32>;
					interrupts = <0x0b 0x02>;
					pinctrl-names = "default";
					pinctrl-0 = <0x33>;
				};
			};

			serial@30a60000 {
				compatible = "fsl,imx8mp-uart\0fsl,imx6q-uart";
				reg = <0x30a60000 0x10000>;
				interrupts = <0x00 0x1d 0x04>;
				clocks = <0x02 0xfe 0x02 0xfe>;
				clock-names = "ipg\0per";
				dmas = <0x29 0x1c 0x04 0x00 0x29 0x1d 0x04 0x00>;
				dma-names = "rx\0tx";
				status = "okay";
				pinctrl-names = "default";
				pinctrl-0 = <0x34>;
				phandle = <0xb3>;
			};

			mailbox@30aa0000 {
				compatible = "fsl,imx8mp-mu\0fsl,imx6sx-mu";
				reg = <0x30aa0000 0x10000>;
				interrupts = <0x00 0x58 0x04>;
				clocks = <0x02 0xd5>;
				#mbox-cells = <0x02>;
				phandle = <0xb4>;
			};

			mailbox@30e60000 {
				compatible = "fsl,imx8mp-mu\0fsl,imx6sx-mu";
				reg = <0x30e60000 0x10000>;
				interrupts = <0x00 0x88 0x04>;
				#mbox-cells = <0x02>;
				status = "disabled";
				phandle = <0x72>;
			};

			i2c@30ad0000 {
				compatible = "fsl,imx8mp-i2c\0fsl,imx21-i2c";
				#address-cells = <0x01>;
				#size-cells = <0x00>;
				reg = <0x30ad0000 0x10000>;
				interrupts = <0x00 0x4c 0x04>;
				clocks = <0x02 0xe7>;
				status = "disabled";
				phandle = <0xb5>;
			};

			i2c@30ae0000 {
				compatible = "fsl,imx8mp-i2c\0fsl,imx21-i2c";
				#address-cells = <0x01>;
				#size-cells = <0x00>;
				reg = <0x30ae0000 0x10000>;
				interrupts = <0x00 0x4d 0x04>;
				clocks = <0x02 0xe8>;
				status = "okay";
				clock-frequency = <0x61a80>;
				pinctrl-names = "default";
				pinctrl-0 = <0x35>;
				phandle = <0xb6>;
			};

			mmc@30b40000 {
				compatible = "fsl,imx8mp-usdhc\0fsl,imx8mm-usdhc\0fsl,imx7d-usdhc";
				reg = <0x30b40000 0x10000>;
				interrupts = <0x00 0x16 0x04>;
				clocks = <0x02 0x00 0x02 0x5f 0x02 0x101>;
				clock-names = "ipg\0ahb\0per";
				fsl,tuning-start-tap = <0x14>;
				fsl,tuning-step = <0x02>;
				bus-width = <0x04>;
				status = "disabled";
				phandle = <0xb7>;
			};

			mmc@30b50000 {
				compatible = "fsl,imx8mp-usdhc\0fsl,imx8mm-usdhc\0fsl,imx7d-usdhc";
				reg = <0x30b50000 0x10000>;
				interrupts = <0x00 0x17 0x04>;
				clocks = <0x02 0x00 0x02 0x5f 0x02 0x102>;
				clock-names = "ipg\0ahb\0per";
				fsl,tuning-start-tap = <0x14>;
				fsl,tuning-step = <0x02>;
				bus-width = <0x04>;
				status = "okay";
				pinctrl-names = "default\0state_100mhz\0state_200mhz";
				pinctrl-0 = <0x36 0x37>;
				pinctrl-1 = <0x38 0x37>;
				pinctrl-2 = <0x39 0x37>;
				cd-gpios = <0x32 0x0c 0x01>;
				vmmc-supply = <0x3a>;
				phandle = <0xb8>;
			};

			mmc@30b60000 {
				compatible = "fsl,imx8mp-usdhc\0fsl,imx8mm-usdhc\0fsl,imx7d-usdhc";
				reg = <0x30b60000 0x10000>;
				interrupts = <0x00 0x18 0x04>;
				clocks = <0x02 0x00 0x02 0x5f 0x02 0x115>;
				clock-names = "ipg\0ahb\0per";
				fsl,tuning-start-tap = <0x14>;
				fsl,tuning-step = <0x02>;
				bus-width = <0x08>;
				status = "okay";
				assigned-clocks = <0x02 0xa9>;
				assigned-clock-rates = <0x17d78400>;
				pinctrl-names = "default\0state_100mhz\0state_200mhz";
				pinctrl-0 = <0x3b>;
				pinctrl-1 = <0x3c>;
				pinctrl-2 = <0x3d>;
				non-removable;
				phandle = <0xb9>;
			};

			spi@30bb0000 {
				compatible = "nxp,imx8mp-fspi";
				reg = <0x30bb0000 0x10000 0x8000000 0x10000000>;
				reg-names = "fspi_base\0fspi_mmap";
				interrupts = <0x00 0x6b 0x04>;
				clocks = <0x02 0xe2 0x02 0xe2>;
				clock-names = "fspi_en\0fspi";
				assigned-clock-rates = <0x4c4b400>;
				assigned-clocks = <0x02 0x87>;
				#address-cells = <0x01>;
				#size-cells = <0x00>;
				status = "disabled";
				phandle = <0xba>;
			};

			dma-controller@30bd0000 {
				compatible = "fsl,imx8mp-sdma\0fsl,imx8mq-sdma";
				reg = <0x30bd0000 0x10000>;
				interrupts = <0x00 0x02 0x04>;
				clocks = <0x02 0xec 0x02 0x6b>;
				clock-names = "ipg\0ahb";
				#dma-cells = <0x03>;
				fsl,sdma-ram-script-name = "imx/sdma/sdma-imx7d.bin";
				phandle = <0x29>;
			};

			ethernet@30be0000 {
				compatible = "fsl,imx8mp-fec\0fsl,imx8mq-fec\0fsl,imx6sx-fec";
				reg = <0x30be0000 0x10000>;
				interrupts = <0x00 0x76 0x04 0x00 0x77 0x04 0x00 0x78 0x04 0x00 0x79 0x04>;
				clocks = <0x02 0xc0 0x02 0xf2 0x02 0x84 0x02 0x83 0x02 0x85>;
				clock-names = "ipg\0ahb\0ptp\0enet_clk_ref\0enet_out";
				assigned-clocks = <0x02 0x5e 0x02 0x84 0x02 0x83 0x02 0x85>;
				assigned-clock-parents = <0x02 0x36 0x02 0x3a 0x02 0x3b 0x02 0x39>;
				assigned-clock-rates = <0x00 0x5f5e100 0x7735940 0x00>;
				fsl,num-tx-queues = <0x03>;
				fsl,num-rx-queues = <0x03>;
				nvmem-cells = <0x3e>;
				nvmem-cell-names = "mac-address";
				fsl,stop-mode = <0x2c 0x10 0x03>;
				status = "disabled";
				phandle = <0xbb>;
			};

			ethernet@30bf0000 {
				compatible = "nxp,imx8mp-dwmac-eqos\0snps,dwmac-5.10a";
				reg = <0x30bf0000 0x10000>;
				interrupts = <0x00 0x87 0x04 0x00 0x86 0x04>;
				interrupt-names = "macirq\0eth_wake_irq";
				clocks = <0x02 0xed 0x02 0xe1 0x02 0x82 0x02 0x81>;
				clock-names = "stmmaceth\0pclk\0ptp_ref\0tx";
				assigned-clocks = <0x02 0x5e 0x02 0x82 0x02 0x81>;
				assigned-clock-parents = <0x02 0x36 0x02 0x3a 0x02 0x3b>;
				assigned-clock-rates = <0x00 0x5f5e100 0x7735940>;
				nvmem-cells = <0x3f>;
				nvmem-cell-names = "mac-address";
				intf_mode = <0x2c 0x04>;
				status = "okay";
				pinctrl-names = "default";
				pinctrl-0 = <0x40>;
				phy-connection-type = "rgmii-id";
				phy-handle = <0x41>;
				phandle = <0xbc>;

				mdio {
					compatible = "snps,dwmac-mdio";
					#address-cells = <0x01>;
					#size-cells = <0x00>;

					ethernet-phy@0 {
						compatible = "ethernet-phy-ieee802.3-c22";
						reg = <0x00>;
						reset-gpios = <0x42 0x12 0x01>;
						reset-assert-us = <0x14>;
						reset-deassert-us = <0x30d40>;
						phandle = <0x41>;
					};
				};
			};
		};

		bus@30c00000 {
			compatible = "fsl,aips-bus\0simple-bus";
			reg = <0x30c00000 0x400000>;
			#address-cells = <0x01>;
			#size-cells = <0x01>;
			ranges;
			phandle = <0xbd>;

			spba-bus@30c00000 {
				compatible = "fsl,spba-bus\0simple-bus";
				reg = <0x30c00000 0x100000>;
				#address-cells = <0x01>;
				#size-cells = <0x01>;
				ranges;

				sai@30c10000 {
					compatible = "fsl,imx8mp-sai\0fsl,imx8mq-sai";
					reg = <0x30c10000 0x10000>;
					#sound-dai-cells = <0x00>;
					clocks = <0x43 0x00 0x02 0x00 0x43 0x01 0x43 0x02 0x43 0x03>;
					clock-names = "bus\0mclk0\0mclk1\0mclk2\0mclk3";
					dmas = <0x44 0x00 0x02 0x00 0x44 0x01 0x02 0x00>;
					dma-names = "rx\0tx";
					interrupts = <0x00 0x5f 0x04>;
					status = "disabled";
					phandle = <0xbe>;
				};

				sai@30c20000 {
					compatible = "fsl,imx8mp-sai\0fsl,imx8mq-sai";
					reg = <0x30c20000 0x10000>;
					#sound-dai-cells = <0x00>;
					clocks = <0x43 0x04 0x02 0x00 0x43 0x05 0x43 0x06 0x43 0x07>;
					clock-names = "bus\0mclk0\0mclk1\0mclk2\0mclk3";
					dmas = <0x44 0x02 0x02 0x00 0x44 0x03 0x02 0x00>;
					dma-names = "rx\0tx";
					interrupts = <0x00 0x60 0x04>;
					status = "disabled";
					phandle = <0xbf>;
				};

				sai@30c30000 {
					compatible = "fsl,imx8mp-sai\0fsl,imx8mq-sai";
					reg = <0x30c30000 0x10000>;
					#sound-dai-cells = <0x00>;
					clocks = <0x43 0x08 0x02 0x00 0x43 0x09 0x43 0x0a 0x43 0x0b>;
					clock-names = "bus\0mclk0\0mclk1\0mclk2\0mclk3";
					dmas = <0x44 0x04 0x02 0x00 0x44 0x05 0x02 0x00>;
					dma-names = "rx\0tx";
					interrupts = <0x00 0x32 0x04>;
					status = "disabled";
					phandle = <0xc0>;
				};

				sai@30c50000 {
					compatible = "fsl,imx8mp-sai\0fsl,imx8mq-sai";
					reg = <0x30c50000 0x10000>;
					#sound-dai-cells = <0x00>;
					clocks = <0x43 0x0c 0x02 0x00 0x43 0x0d 0x43 0x0e 0x43 0x0f>;
					clock-names = "bus\0mclk0\0mclk1\0mclk2\0mclk3";
					dmas = <0x44 0x08 0x02 0x00 0x44 0x09 0x02 0x00>;
					dma-names = "rx\0tx";
					interrupts = <0x00 0x5a 0x04>;
					status = "disabled";
					phandle = <0xc1>;
				};

				sai@30c60000 {
					compatible = "fsl,imx8mp-sai\0fsl,imx8mq-sai";
					reg = <0x30c60000 0x10000>;
					#sound-dai-cells = <0x00>;
					clocks = <0x43 0x10 0x02 0x00 0x43 0x11 0x43 0x12 0x43 0x13>;
					clock-names = "bus\0mclk0\0mclk1\0mclk2\0mclk3";
					dmas = <0x44 0x0a 0x02 0x00 0x44 0x0b 0x02 0x00>;
					dma-names = "rx\0tx";
					interrupts = <0x00 0x5a 0x04>;
					status = "disabled";
					phandle = <0xc2>;
				};

				sai@30c80000 {
					compatible = "fsl,imx8mp-sai\0fsl,imx8mq-sai";
					reg = <0x30c80000 0x10000>;
					#sound-dai-cells = <0x00>;
					clocks = <0x43 0x14 0x02 0x00 0x43 0x15 0x43 0x16 0x43 0x17>;
					clock-names = "bus\0mclk0\0mclk1\0mclk2\0mclk3";
					dmas = <0x44 0x0c 0x02 0x00 0x44 0x0d 0x02 0x00>;
					dma-names = "rx\0tx";
					interrupts = <0x00 0x6f 0x04>;
					status = "disabled";
					phandle = <0xc3>;
				};
			};

			dma-controller@30e00000 {
				compatible = "fsl,imx8mp-sdma\0fsl,imx8mq-sdma";
				reg = <0x30e00000 0x10000>;
				#dma-cells = <0x03>;
				clocks = <0x43 0x1b 0x02 0x11c>;
				clock-names = "ipg\0ahb";
				interrupts = <0x00 0x22 0x04>;
				fsl,sdma-ram-script-name = "imx/sdma/sdma-imx7d.bin";
				phandle = <0xc4>;
			};

			dma-controller@30e10000 {
				compatible = "fsl,imx8mp-sdma\0fsl,imx8mq-sdma";
				reg = <0x30e10000 0x10000>;
				#dma-cells = <0x03>;
				clocks = <0x43 0x1a 0x02 0x11c>;
				clock-names = "ipg\0ahb";
				interrupts = <0x00 0x67 0x04>;
				fsl,sdma-ram-script-name = "imx/sdma/sdma-imx7d.bin";
				phandle = <0x44>;
			};

			clock-controller@30e20000 {
				compatible = "fsl,imx8mp-audio-blk-ctrl";
				reg = <0x30e20000 0x10000>;
				#clock-cells = <0x01>;
				clocks = <0x02 0x11c 0x02 0x7b 0x02 0x7c 0x02 0x7d 0x02 0x7f 0x02 0x80 0x02 0xb6>;
				clock-names = "ahb\0sai1\0sai2\0sai3\0sai5\0sai6\0sai7";
				power-domains = <0x45>;
				phandle = <0x43>;
			};
		};

		interconnect@32700000 {
			compatible = "fsl,imx8mp-noc\0fsl,imx8m-noc";
			reg = <0x32700000 0x100000>;
			clocks = <0x02 0x67>;
			#interconnect-cells = <0x01>;
			operating-points-v2 = <0x46>;
			phandle = <0x53>;

			opp-table {
				compatible = "operating-points-v2";
				phandle = <0x46>;

				opp-200000000 {
					opp-hz = <0x00 0xbebc200>;
				};

				opp-1000000000 {
					opp-hz = <0x00 0x3b9aca00>;
				};
			};
		};

		bus@32c00000 {
			compatible = "fsl,aips-bus\0simple-bus";
			reg = <0x32c00000 0x400000>;
			#address-cells = <0x01>;
			#size-cells = <0x01>;
			ranges;
			phandle = <0xc5>;

			isi@32e00000 {
				compatible = "fsl,imx8mp-isi";
				reg = <0x32e00000 0x4000>;
				interrupts = <0x00 0x10 0x04 0x00 0x2a 0x04>;
				clocks = <0x02 0x10e 0x02 0x10d>;
				clock-names = "axi\0apb";
				fsl,blk-ctrl = <0x47>;
				power-domains = <0x47 0x03>;
				status = "okay";
				phandle = <0xc6>;

				ports {
					#address-cells = <0x01>;
					#size-cells = <0x00>;

					port@0 {
						reg = <0x00>;

						endpoint {
							remote-endpoint = <0x48>;
							phandle = <0x4a>;
						};
					};

					port@1 {
						reg = <0x01>;

						endpoint {
							remote-endpoint = <0x49>;
							phandle = <0x4b>;
						};
					};
				};
			};

			isp@32e10000 {
				compatible = "fsl,imx8mp-isp";
				reg = <0x32e10000 0x10000>;
				interrupts = <0x00 0x4a 0x04>;
				clocks = <0x02 0x114 0x02 0x10e 0x02 0x10d>;
				clock-names = "isp\0aclk\0hclk";
				assigned-clocks = <0x02 0x138>;
				assigned-clock-parents = <0x02 0x40>;
				assigned-clock-rates = <0x1dcd6500>;
				power-domains = <0x47 0x06>;
				fsl,blk-ctrl = <0x47 0x00>;
				status = "okay";
				phandle = <0xc7>;

				ports {
					#address-cells = <0x01>;
					#size-cells = <0x00>;

					port@1 {
						reg = <0x01>;

						endpoint {
							phandle = <0xe2>;
							remote-endpoint = <0x48>;
							bus-type = <0x05>;
						};
					};
				};
			};

			isp@32e20000 {
				compatible = "fsl,imx8mp-isp";
				reg = <0x32e20000 0x10000>;
				interrupts = <0x00 0x4b 0x04>;
				clocks = <0x02 0x114 0x02 0x10e 0x02 0x10d>;
				clock-names = "isp\0aclk\0hclk";
				assigned-clocks = <0x02 0x138>;
				assigned-clock-parents = <0x02 0x40>;
				assigned-clock-rates = <0x1dcd6500>;
				power-domains = <0x47 0x06>;
				fsl,blk-ctrl = <0x47 0x01>;
				status = "disabled";
				phandle = <0xc8>;

				ports {
					#address-cells = <0x01>;
					#size-cells = <0x00>;

					port@1 {
						reg = <0x01>;
					};
				};
			};

			dwe@32e30000 {
				compatible = "nxp,imx8mp-dw100";
				reg = <0x32e30000 0x10000>;
				interrupts = <0x00 0x64 0x04>;
				clocks = <0x02 0x10e 0x02 0x10d>;
				clock-names = "axi\0ahb";
				power-domains = <0x47 0x07>;
				phandle = <0xc9>;
			};

			csi@32e40000 {
				compatible = "fsl,imx8mp-mipi-csi2\0fsl,imx8mm-mipi-csi2";
				reg = <0x32e40000 0x10000>;
				interrupts = <0x00 0x11 0x04>;
				clock-frequency = <0x1dcd6500>;
				clocks = <0x02 0x10d 0x02 0x10f 0x02 0x113 0x02 0x10e>;
				clock-names = "pclk\0wrap\0phy\0axi";
				assigned-clocks = <0x02 0xaa>;
				assigned-clock-parents = <0x02 0x41>;
				assigned-clock-rates = <0x1dcd6500>;
				power-domains = <0x47 0x01>;
				status = "okay";
				phandle = <0xca>;

				ports {
					#address-cells = <0x01>;
					#size-cells = <0x00>;

					port@0 {
						reg = <0x00>;

						endpoint {
							phandle = <0xe8>;
							data-lanes = <0x01 0x02 0x03 0x04>;
							clock-lanes = <0x00>;
							remote-endpoint = <0xe9>;
						};
					};

					port@1 {
						reg = <0x01>;

						endpoint {
							remote-endpoint = <0xe2>;
							phandle = <0x48>;
						};
					};
				};
			};

			csi@32e50000 {
				compatible = "fsl,imx8mp-mipi-csi2\0fsl,imx8mm-mipi-csi2";
				reg = <0x32e50000 0x10000>;
				interrupts = <0x00 0x50 0x04>;
				clock-frequency = <0xfdad680>;
				clocks = <0x02 0x10d 0x02 0x110 0x02 0x113 0x02 0x10e>;
				clock-names = "pclk\0wrap\0phy\0axi";
				assigned-clocks = <0x02 0xad>;
				assigned-clock-parents = <0x02 0x41>;
				assigned-clock-rates = <0xfdad680>;
				power-domains = <0x47 0x04>;
				status = "disabled";
				phandle = <0xcb>;

				ports {
					#address-cells = <0x01>;
					#size-cells = <0x00>;

					port@0 {
						reg = <0x00>;
					};

					port@1 {
						reg = <0x01>;

						endpoint {
							remote-endpoint = <0x4b>;
							phandle = <0x49>;
						};
					};
				};
			};

			dsi@32e60000 {
				compatible = "fsl,imx8mp-mipi-dsim";
				reg = <0x32e60000 0x400>;
				clocks = <0x02 0x10d 0x02 0xab>;
				clock-names = "bus_clk\0sclk_mipi";
				assigned-clocks = <0x02 0x62 0x02 0xab>;
				assigned-clock-parents = <0x02 0x38 0x02 0x02>;
				assigned-clock-rates = <0xbebc200 0x16e3600>;
				samsung,pll-clock-frequency = <0x16e3600>;
				interrupts = <0x00 0x12 0x04>;
				power-domains = <0x47 0x00>;
				status = "disabled";
				phandle = <0xcc>;

				ports {
					#address-cells = <0x01>;
					#size-cells = <0x00>;

					port@0 {
						reg = <0x00>;

						endpoint {
							remote-endpoint = <0x4c>;
							phandle = <0x4d>;
						};
					};
				};
			};

			display-controller@32e80000 {
				compatible = "fsl,imx8mp-lcdif";
				reg = <0x32e80000 0x10000>;
				clocks = <0x02 0x111 0x02 0x10d 0x02 0x10e>;
				clock-names = "pix\0axi\0disp_axi";
				interrupts = <0x00 0x05 0x04>;
				power-domains = <0x47 0x02>;
				status = "disabled";
				phandle = <0xcd>;

				port {

					endpoint {
						remote-endpoint = <0x4d>;
						phandle = <0x4c>;
					};
				};
			};

			display-controller@32e90000 {
				compatible = "fsl,imx8mp-lcdif";
				reg = <0x32e90000 0x10000>;
				interrupts = <0x00 0x06 0x04>;
				clocks = <0x02 0x112 0x02 0x10d 0x02 0x10e>;
				clock-names = "pix\0axi\0disp_axi";
				power-domains = <0x47 0x05>;
				status = "disabled";
				phandle = <0xce>;

				port {

					endpoint {
						remote-endpoint = <0x4e>;
						phandle = <0x54>;
					};
				};
			};

			blk-ctrl@32ec0000 {
				compatible = "fsl,imx8mp-media-blk-ctrl\0syscon";
				reg = <0x32ec0000 0x10000>;
				#address-cells = <0x01>;
				#size-cells = <0x01>;
				power-domains = <0x4f 0x50 0x50 0x4f 0x4f 0x51 0x4f 0x52 0x52 0x51>;
				power-domain-names = "bus\0mipi-dsi1\0mipi-csi1\0lcdif1\0isi\0mipi-csi2\0lcdif2\0isp\0dwe\0mipi-dsi2";
				interconnects = <0x53 0x1c 0x53 0x1b 0x53 0x1d 0x53 0x1b 0x53 0x1e 0x53 0x1b 0x53 0x1f 0x53 0x1b 0x53 0x20 0x53 0x1b 0x53 0x21 0x53 0x1b 0x53 0x22 0x53 0x1b 0x53 0x23 0x53 0x1b>;
				interconnect-names = "lcdif-rd\0lcdif-wr\0isi0\0isi1\0isi2\0isp0\0isp1\0dwe";
				clocks = <0x02 0x10d 0x02 0x10e 0x02 0x10f 0x02 0x110 0x02 0x111 0x02 0x112 0x02 0x114 0x02 0x113>;
				clock-names = "apb\0axi\0cam1\0cam2\0disp1\0disp2\0isp\0phy";
				assigned-clocks = <0x02 0x61 0x02 0x62 0x02 0xac 0x02 0x139 0x02 0x14>;
				assigned-clock-parents = <0x02 0x41 0x02 0x38 0x02 0x28 0x02 0x28>;
				assigned-clock-rates = <0x1dcd6500 0xbebc200 0x00 0x00 0x3df582e0>;
				#power-domain-cells = <0x01>;
				phandle = <0x47>;

				bridge@5c {
					compatible = "fsl,imx8mp-ldb";
					reg = <0x5c 0x04 0x128 0x04>;
					reg-names = "ldb\0lvds";
					clocks = <0x02 0xae>;
					clock-names = "ldb";
					assigned-clocks = <0x02 0xae>;
					assigned-clock-parents = <0x02 0x28>;
					status = "disabled";
					phandle = <0xcf>;

					ports {
						#address-cells = <0x01>;
						#size-cells = <0x00>;

						port@0 {
							reg = <0x00>;

							endpoint {
								remote-endpoint = <0x54>;
								phandle = <0x4e>;
							};
						};

						port@1 {
							reg = <0x01>;

							endpoint {
								phandle = <0xd0>;
							};
						};

						port@2 {
							reg = <0x02>;

							endpoint {
								phandle = <0xd1>;
							};
						};
					};
				};
			};

			pcie-phy@32f00000 {
				compatible = "fsl,imx8mp-pcie-phy";
				reg = <0x32f00000 0x10000>;
				resets = <0x55 0x18 0x55 0x19>;
				reset-names = "pciephy\0perst";
				power-domains = <0x56 0x04>;
				#phy-cells = <0x00>;
				status = "disabled";
				phandle = <0x65>;
			};

			blk-ctrl@32f10000 {
				compatible = "fsl,imx8mp-hsio-blk-ctrl\0syscon";
				reg = <0x32f10000 0x24>;
				clocks = <0x02 0xff 0x02 0xd9>;
				clock-names = "usb\0pcie";
				power-domains = <0x57 0x57 0x58 0x59 0x57 0x5a>;
				power-domain-names = "bus\0usb\0usb-phy1\0usb-phy2\0pcie\0pcie-phy";
				interconnects = <0x53 0x17 0x53 0x16 0x53 0x18 0x53 0x16 0x53 0x19 0x53 0x16 0x53 0x1a 0x53 0x16>;
				interconnect-names = "noc-pcie\0usb1\0usb2\0pcie";
				#power-domain-cells = <0x01>;
				#clock-cells = <0x00>;
				phandle = <0x56>;
			};

			blk-ctrl@32fc0000 {
				compatible = "fsl,imx8mp-hdmi-blk-ctrl\0syscon";
				reg = <0x32fc0000 0x23c>;
				clocks = <0x02 0x63 0x02 0x116 0x02 0xa8 0x02 0xa7>;
				clock-names = "apb\0axi\0ref_266m\0ref_24m";
				power-domains = <0x5b 0x5b 0x5b 0x5b 0x5b 0x5b 0x5b 0x5c>;
				power-domain-names = "bus\0irqsteer\0lcdif\0pai\0pvi\0trng\0hdmi-tx\0hdmi-tx-phy";
				#power-domain-cells = <0x01>;
				phandle = <0x5d>;
			};

			interrupt-controller@32fc2000 {
				compatible = "fsl,imx-irqsteer";
				reg = <0x32fc2000 0x44>;
				interrupts = <0x00 0x2b 0x04>;
				interrupt-controller;
				#interrupt-cells = <0x01>;
				fsl,channel = <0x01>;
				fsl,num-irqs = <0x40>;
				clocks = <0x02 0x63>;
				clock-names = "ipg";
				power-domains = <0x5d 0x00>;
				phandle = <0x60>;
			};

			display-bridge@32fc4000 {
				compatible = "fsl,imx8mp-hdmi-pvi";
				reg = <0x32fc4000 0x40>;
				power-domains = <0x5d 0x03>;
				status = "okay";
				phandle = <0xd2>;

				ports {
					#address-cells = <0x01>;
					#size-cells = <0x00>;

					port@0 {
						reg = <0x00>;

						endpoint {
							remote-endpoint = <0x5e>;
							phandle = <0x62>;
						};
					};

					port@1 {
						reg = <0x01>;

						endpoint {
							remote-endpoint = <0x5f>;
							phandle = <0x64>;
						};
					};
				};
			};

			display-controller@32fc6000 {
				compatible = "fsl,imx8mp-lcdif";
				reg = <0x32fc6000 0x238>;
				interrupts = <0x08 0x04>;
				interrupt-parent = <0x60>;
				clocks = <0x61 0x02 0x63 0x02 0x116>;
				clock-names = "pix\0axi\0disp_axi";
				power-domains = <0x5d 0x01>;
				status = "okay";
				phandle = <0xd3>;

				port {

					endpoint {
						remote-endpoint = <0x62>;
						phandle = <0x5e>;
					};
				};
			};

			hdmi@32fd8000 {
				compatible = "fsl,imx8mp-hdmi";
				reg = <0x32fd8000 0x7eff>;
				interrupts = <0x00 0x04>;
				interrupt-parent = <0x60>;
				clocks = <0x02 0x63 0x02 0xa8 0x02 0xa6 0x02 0x01 0x61>;
				clock-names = "iahb\0isfr\0fdcc\0cec\0pix";
				assigned-clocks = <0x02 0xa8>;
				assigned-clock-parents = <0x02 0x36>;
				power-domains = <0x5d 0x05>;
				reg-io-width = <0x01>;
				status = "okay";
				pinctrl-names = "default";
				pinctrl-0 = <0x63>;
				phandle = <0xd4>;

				port {

					endpoint {
						remote-endpoint = <0x64>;
						phandle = <0x5f>;
					};
				};
			};

			phy@32fdff00 {
				compatible = "fsl,imx8mp-hdmi-phy";
				reg = <0x32fdff00 0x100>;
				clocks = <0x02 0x63 0x02 0xa7>;
				clock-names = "apb\0ref";
				assigned-clocks = <0x02 0xa7>;
				assigned-clock-parents = <0x02 0x02>;
				power-domains = <0x5d 0x06>;
				#clock-cells = <0x00>;
				#phy-cells = <0x00>;
				status = "okay";
				phandle = <0x61>;
			};
		};

		pcie@33800000 {
			compatible = "fsl,imx8mp-pcie";
			reg = <0x33800000 0x400000 0x1ff00000 0x80000>;
			reg-names = "dbi\0config";
			clocks = <0x02 0x10c 0x02 0x137 0x02 0xd9>;
			clock-names = "pcie\0pcie_bus\0pcie_aux";
			assigned-clocks = <0x02 0x78>;
			assigned-clock-rates = <0x989680>;
			assigned-clock-parents = <0x02 0x39>;
			#address-cells = <0x03>;
			#size-cells = <0x02>;
			device_type = "pci";
			bus-range = <0x00 0xff>;
			ranges = <0x81000000 0x00 0x00 0x1ff80000 0x00 0x10000 0x82000000 0x00 0x18000000 0x18000000 0x00 0x7f00000>;
			num-lanes = <0x01>;
			num-viewport = <0x04>;
			interrupts = <0x00 0x8c 0x04>;
			interrupt-names = "msi";
			#interrupt-cells = <0x01>;
			interrupt-map-mask = <0x00 0x00 0x00 0x07>;
			interrupt-map = <0x00 0x00 0x00 0x01 0x01 0x00 0x7e 0x04 0x00 0x00 0x00 0x02 0x01 0x00 0x7d 0x04 0x00 0x00 0x00 0x03 0x01 0x00 0x7c 0x04 0x00 0x00 0x00 0x04 0x01 0x00 0x7b 0x04>;
			fsl,max-link-speed = <0x03>;
			linux,pci-domain = <0x00>;
			power-domains = <0x56 0x03>;
			resets = <0x55 0x1a 0x55 0x1b>;
			reset-names = "apps\0turnoff";
			phys = <0x65>;
			phy-names = "pcie-phy";
			status = "disabled";
			phandle = <0xd5>;
		};

		pcie-ep@33800000 {
			compatible = "fsl,imx8mp-pcie-ep";
			reg = <0x33800000 0x400000 0x18000000 0x8000000>;
			reg-names = "dbi\0addr_space";
			clocks = <0x02 0x10c 0x02 0x137 0x02 0xd9>;
			clock-names = "pcie\0pcie_bus\0pcie_aux";
			assigned-clocks = <0x02 0x78>;
			assigned-clock-rates = <0x989680>;
			assigned-clock-parents = <0x02 0x39>;
			num-lanes = <0x01>;
			interrupts = <0x00 0x7f 0x04>;
			interrupt-names = "dma";
			fsl,max-link-speed = <0x03>;
			power-domains = <0x56 0x03>;
			resets = <0x55 0x1a 0x55 0x1b>;
			reset-names = "apps\0turnoff";
			phys = <0x65>;
			phy-names = "pcie-phy";
			num-ib-windows = <0x04>;
			num-ob-windows = <0x04>;
			status = "disabled";
			phandle = <0xd6>;
		};

		gpu@38000000 {
			compatible = "vivante,gc";
			reg = <0x38000000 0x8000>;
			interrupts = <0x00 0x03 0x04>;
			clocks = <0x02 0xf8 0x02 0x134 0x02 0x107 0x02 0x66>;
			clock-names = "core\0shader\0bus\0reg";
			assigned-clocks = <0x02 0x133 0x02 0x134>;
			assigned-clock-parents = <0x02 0x38 0x02 0x38>;
			assigned-clock-rates = <0x2faf0800 0x2faf0800>;
			power-domains = <0x66>;
			phandle = <0xd7>;
		};

		gpu@38008000 {
			compatible = "vivante,gc";
			reg = <0x38008000 0x8000>;
			interrupts = <0x00 0x19 0x04>;
			clocks = <0x02 0xf7 0x02 0x107 0x02 0x66>;
			clock-names = "core\0bus\0reg";
			assigned-clocks = <0x02 0x135>;
			assigned-clock-parents = <0x02 0x38>;
			assigned-clock-rates = <0x2faf0800>;
			power-domains = <0x67>;
			phandle = <0xd8>;
		};

		video-codec@38300000 {
			compatible = "nxp,imx8mm-vpu-g1";
			reg = <0x38300000 0x10000>;
			interrupts = <0x00 0x07 0x04>;
			clocks = <0x02 0x106>;
			assigned-clocks = <0x02 0x72>;
			assigned-clock-parents = <0x02 0x2b>;
			assigned-clock-rates = <0x23c34600>;
			power-domains = <0x68 0x00>;
			phandle = <0xd9>;
		};

		video-codec@38310000 {
			compatible = "nxp,imx8mq-vpu-g2";
			reg = <0x38310000 0x10000>;
			interrupts = <0x00 0x08 0x04>;
			clocks = <0x02 0x10a>;
			assigned-clocks = <0x02 0x73>;
			assigned-clock-parents = <0x02 0x41>;
			assigned-clock-rates = <0x1dcd6500>;
			power-domains = <0x68 0x01>;
			phandle = <0xda>;
		};

		blk-ctrl@38330000 {
			compatible = "fsl,imx8mp-vpu-blk-ctrl\0syscon";
			reg = <0x38330000 0x100>;
			#power-domain-cells = <0x01>;
			power-domains = <0x28 0x69 0x6a 0x6b>;
			power-domain-names = "bus\0g1\0g2\0vc8000e";
			clocks = <0x02 0x106 0x02 0x10a 0x02 0x109>;
			clock-names = "g1\0g2\0vc8000e";
			assigned-clocks = <0x02 0x60 0x02 0x17>;
			assigned-clock-parents = <0x02 0x2b>;
			assigned-clock-rates = <0x23c34600 0x23c34600>;
			interconnects = <0x53 0x25 0x53 0x24 0x53 0x26 0x53 0x24 0x53 0x27 0x53 0x24>;
			interconnect-names = "g1\0g2\0vc8000e";
			phandle = <0x68>;
		};

		interrupt-controller@38800000 {
			compatible = "arm,gic-v3";
			reg = <0x38800000 0x10000 0x38880000 0xc0000>;
			#interrupt-cells = <0x03>;
			interrupt-controller;
			interrupts = <0x01 0x09 0x04>;
			interrupt-parent = <0x01>;
			phandle = <0x01>;
		};

		memory-controller@3d400000 {
			compatible = "snps,ddrc-3.80a";
			reg = <0x3d400000 0x400000>;
			interrupts = <0x00 0x93 0x04>;
			phandle = <0xdb>;
		};

		ddr-pmu@3d800000 {
			compatible = "fsl,imx8mp-ddr-pmu\0fsl,imx8m-ddr-pmu";
			reg = <0x3d800000 0x400000>;
			interrupts = <0x00 0x62 0x04>;
		};

		usb-phy@381f0040 {
			compatible = "fsl,imx8mp-usb-phy";
			reg = <0x381f0040 0x40>;
			clocks = <0x02 0x100>;
			clock-names = "phy";
			assigned-clocks = <0x02 0x93>;
			assigned-clock-parents = <0x02 0x02>;
			power-domains = <0x56 0x01>;
			#phy-cells = <0x00>;
			status = "disabled";
			phandle = <0x6c>;
		};

		usb@32f10100 {
			compatible = "fsl,imx8mp-dwc3";
			reg = <0x32f10100 0x08 0x381f0000 0x20>;
			clocks = <0x02 0x10c 0x02 0x140>;
			clock-names = "hsio\0suspend";
			interrupts = <0x00 0x94 0x04>;
			power-domains = <0x56 0x00>;
			#address-cells = <0x01>;
			#size-cells = <0x01>;
			dma-ranges = <0x40000000 0x40000000 0xc0000000>;
			ranges;
			status = "disabled";
			phandle = <0xdc>;

			usb@38100000 {
				compatible = "snps,dwc3";
				reg = <0x38100000 0x10000>;
				clocks = <0x02 0xff 0x02 0x92 0x02 0x140>;
				clock-names = "bus_early\0ref\0suspend";
				interrupts = <0x00 0x28 0x04>;
				power-domains = <0x56 0x00>;
				phys = <0x6c 0x6c>;
				phy-names = "usb2-phy\0usb3-phy";
				snps,gfladj-refclk-lpm-sel-quirk;
				phandle = <0xdd>;
			};
		};

		usb-phy@382f0040 {
			compatible = "fsl,imx8mp-usb-phy";
			reg = <0x382f0040 0x40>;
			clocks = <0x02 0x100>;
			clock-names = "phy";
			assigned-clocks = <0x02 0x93>;
			assigned-clock-parents = <0x02 0x02>;
			power-domains = <0x56 0x02>;
			#phy-cells = <0x00>;
			status = "okay";
			phandle = <0x6d>;
		};

		usb@32f10108 {
			compatible = "fsl,imx8mp-dwc3";
			reg = <0x32f10108 0x08 0x382f0000 0x20>;
			clocks = <0x02 0x10c 0x02 0x140>;
			clock-names = "hsio\0suspend";
			interrupts = <0x00 0x95 0x04>;
			power-domains = <0x56 0x00>;
			#address-cells = <0x01>;
			#size-cells = <0x01>;
			dma-ranges = <0x40000000 0x40000000 0xc0000000>;
			ranges;
			status = "okay";
			phandle = <0xde>;

			usb@38200000 {
				compatible = "snps,dwc3";
				reg = <0x38200000 0x10000>;
				clocks = <0x02 0xff 0x02 0x92 0x02 0x140>;
				clock-names = "bus_early\0ref\0suspend";
				interrupts = <0x00 0x29 0x04>;
				power-domains = <0x56 0x00>;
				phys = <0x6d 0x6d>;
				phy-names = "usb2-phy\0usb3-phy";
				snps,gfladj-refclk-lpm-sel-quirk;
				#address-cells = <0x01>;
				#size-cells = <0x00>;
				pinctrl-names = "default";
				pinctrl-0 = <0x6e>;
				dr_mode = "host";
				status = "okay";
				phandle = <0xdf>;

				hub@1 {
					compatible = "usbbda,5411";
					reg = <0x01>;
					reset-gpios = <0x42 0x19 0x01>;
					vdd-supply = <0x6f>;
					peer-hub = <0x70>;
					phandle = <0x71>;
				};

				hub@2 {
					compatible = "usbbda,411";
					reg = <0x02>;
					reset-gpios = <0x42 0x19 0x01>;
					vdd-supply = <0x6f>;
					peer-hub = <0x71>;
					phandle = <0x70>;
				};
			};
		};

		dsp@3b6e8000 {
			compatible = "fsl,imx8mp-dsp";
			reg = <0x3b6e8000 0x88000>;
			mbox-names = "txdb0\0txdb1\0rxdb0\0rxdb1";
			mboxes = <0x72 0x02 0x00 0x72 0x02 0x01 0x72 0x03 0x00 0x72 0x03 0x01>;
			memory-region = <0x73>;
			status = "disabled";
			phandle = <0xe0>;
		};
	};

	chosen {
		stdout-path = "/soc@0/bus@30800000/spba-bus@30800000/serial@30890000";
	};

	leds {
		compatible = "gpio-leds";
		pinctrl-names = "default";
		pinctrl-0 = <0x74>;

		led-0 {
			function = "power";
			color = <0x01>;
			gpios = <0x75 0x10 0x00>;
			default-state = "on";
		};
	};

	regulator-usdhc2 {
		compatible = "regulator-fixed";
		pinctrl-names = "default";
		pinctrl-0 = <0x76>;
		regulator-name = "VSD_3V3";
		regulator-min-microvolt = <0x325aa0>;
		regulator-max-microvolt = <0x325aa0>;
		gpio = <0x32 0x13 0x00>;
		enable-active-high;
		phandle = <0x3a>;
	};

	regulator-usb-hub {
		compatible = "regulator-fixed";
		pinctrl-names = "default";
		pinctrl-0 = <0x77>;
		regulator-name = "USB_HUB";
		regulator-min-microvolt = <0x4c4b40>;
		regulator-max-microvolt = <0x4c4b40>;
		gpio = <0x42 0x1a 0x00>;
		enable-active-high;
		phandle = <0x6f>;
	};

	__symbols__ {
		mipi_csi_0_in = "/soc@0/bus@32c00000/csi@32e40000/ports/port@0/endpoint";
		pinctrl_i2c2 = "/soc@0/bus@30000000/pinctrl@30330000/i2c2grp";
		pinctrl_csi0_rst = "/soc@0/bus@30000000/pinctrl@30330000/csi0_rst_grp";
		pinctrl_csi0_pwn = "/soc@0/bus@30000000/pinctrl@30330000/csi0_pwn_grp";
		imx335_out = "/soc@0/bus@30800000/i2c@30a30000/camera@1a/port/endpoint";
		csi_3v3 = "/regulator-csi-3v3";
		imx335_clk = "/imx335-clk";
		isp0_in = "/soc@0/bus@32c00000/isp@32e10000/ports/port@1/endpoint";
		A53_0 = "/cpus/cpu@0";
		A53_1 = "/cpus/cpu@1";
		A53_2 = "/cpus/cpu@2";
		A53_3 = "/cpus/cpu@3";
		A53_L2 = "/cpus/l2-cache0";
		a53_opp_table = "/opp-table";
		osc_32k = "/clock-osc-32k";
		osc_24m = "/clock-osc-24m";
		clk_ext1 = "/clock-ext1";
		clk_ext2 = "/clock-ext2";
		clk_ext3 = "/clock-ext3";
		clk_ext4 = "/clock-ext4";
		dsp_reserved = "/reserved-memory/dsp@92400000";
		cpu_alert0 = "/thermal-zones/cpu-thermal/trips/trip0";
		cpu_crit0 = "/thermal-zones/cpu-thermal/trips/trip1";
		soc_alert0 = "/thermal-zones/soc-thermal/trips/trip0";
		soc_crit0 = "/thermal-zones/soc-thermal/trips/trip1";
		soc = "/soc@0";
		etm0 = "/soc@0/etm@28440000";
		etm0_out_port = "/soc@0/etm@28440000/out-ports/port/endpoint";
		etm1 = "/soc@0/etm@28540000";
		etm1_out_port = "/soc@0/etm@28540000/out-ports/port/endpoint";
		etm2 = "/soc@0/etm@28640000";
		etm2_out_port = "/soc@0/etm@28640000/out-ports/port/endpoint";
		etm3 = "/soc@0/etm@28740000";
		etm3_out_port = "/soc@0/etm@28740000/out-ports/port/endpoint";
		ca_funnel_in_port0 = "/soc@0/funnel/in-ports/port@0/endpoint";
		ca_funnel_in_port1 = "/soc@0/funnel/in-ports/port@1/endpoint";
		ca_funnel_in_port2 = "/soc@0/funnel/in-ports/port@2/endpoint";
		ca_funnel_in_port3 = "/soc@0/funnel/in-ports/port@3/endpoint";
		ca_funnel_out_port0 = "/soc@0/funnel/out-ports/port/endpoint";
		hugo_funnel_in_port0 = "/soc@0/funnel@28c03000/in-ports/port@0/endpoint";
		hugo_funnel_in_port1 = "/soc@0/funnel@28c03000/in-ports/port@1/endpoint";
		hugo_funnel_in_port2 = "/soc@0/funnel@28c03000/in-ports/port@2/endpoint";
		hugo_funnel_out_port0 = "/soc@0/funnel@28c03000/out-ports/port/endpoint";
		etf_in_port = "/soc@0/etf@28c04000/in-ports/port/endpoint";
		etf_out_port = "/soc@0/etf@28c04000/out-ports/port/endpoint";
		etr_in_port = "/soc@0/etr@28c06000/in-ports/port/endpoint";
		aips1 = "/soc@0/bus@30000000";
		gpio1 = "/soc@0/bus@30000000/gpio@30200000";
		gpio2 = "/soc@0/bus@30000000/gpio@30210000";
		gpio3 = "/soc@0/bus@30000000/gpio@30220000";
		gpio4 = "/soc@0/bus@30000000/gpio@30230000";
		gpio5 = "/soc@0/bus@30000000/gpio@30240000";
		tmu = "/soc@0/bus@30000000/tmu@30260000";
		wdog1 = "/soc@0/bus@30000000/watchdog@30280000";
		wdog2 = "/soc@0/bus@30000000/watchdog@30290000";
		wdog3 = "/soc@0/bus@30000000/watchdog@302a0000";
		gpt1 = "/soc@0/bus@30000000/timer@302d0000";
		gpt2 = "/soc@0/bus@30000000/timer@302e0000";
		gpt3 = "/soc@0/bus@30000000/timer@302f0000";
		iomuxc = "/soc@0/bus@30000000/pinctrl@30330000";
		pinctrl_eqos = "/soc@0/bus@30000000/pinctrl@30330000/eqosgrp";
		pinctrl_gpio_led = "/soc@0/bus@30000000/pinctrl@30330000/gpioledgrp";
		pinctrl_hdmi = "/soc@0/bus@30000000/pinctrl@30330000/hdmigrp";
		pinctrl_i2c1 = "/soc@0/bus@30000000/pinctrl@30330000/i2c1grp";
		pinctrl_i2c3 = "/soc@0/bus@30000000/pinctrl@30330000/i2c3grp";
		pinctrl_i2c4 = "/soc@0/bus@30000000/pinctrl@30330000/i2c4grp";
		pinctrl_i2c6 = "/soc@0/bus@30000000/pinctrl@30330000/i2c6grp";
		pinctrl_pmic = "/soc@0/bus@30000000/pinctrl@30330000/pmicirqgrp";
		pinctrl_reg_usdhc2_vmmc = "/soc@0/bus@30000000/pinctrl@30330000/regusdhc2vmmcgrp";
		pinctrl_reg_usb_hub = "/soc@0/bus@30000000/pinctrl@30330000/regusbhubgrp";
		pinctrl_rtc_int = "/soc@0/bus@30000000/pinctrl@30330000/rtcintgrp";
		pinctrl_uart2 = "/soc@0/bus@30000000/pinctrl@30330000/uart2grp";
		pinctrl_uart3 = "/soc@0/bus@30000000/pinctrl@30330000/uart3grp";
		pinctrl_uart4 = "/soc@0/bus@30000000/pinctrl@30330000/uart4grp";
		pinctrl_usb1 = "/soc@0/bus@30000000/pinctrl@30330000/usb1grp";
		pinctrl_usdhc2 = "/soc@0/bus@30000000/pinctrl@30330000/usdhc2grp";
		pinctrl_usdhc2_100mhz = "/soc@0/bus@30000000/pinctrl@30330000/usdhc2-100mhzgrp";
		pinctrl_usdhc2_200mhz = "/soc@0/bus@30000000/pinctrl@30330000/usdhc2-200mhzgrp";
		pinctrl_usdhc2_gpio = "/soc@0/bus@30000000/pinctrl@30330000/usdhc2gpiogrp";
		pinctrl_usdhc3 = "/soc@0/bus@30000000/pinctrl@30330000/usdhc3grp";
		pinctrl_usdhc3_100mhz = "/soc@0/bus@30000000/pinctrl@30330000/usdhc3-100mhzgrp";
		pinctrl_usdhc3_200mhz = "/soc@0/bus@30000000/pinctrl@30330000/usdhc3-200mhzgrp";
		pinctrl_wdog = "/soc@0/bus@30000000/pinctrl@30330000/wdoggrp";
		gpr = "/soc@0/bus@30000000/syscon@30340000";
		ocotp = "/soc@0/bus@30000000/efuse@30350000";
		imx8mp_uid = "/soc@0/bus@30000000/efuse@30350000/unique-id@8";
		cpu_speed_grade = "/soc@0/bus@30000000/efuse@30350000/speed-grade@10";
		eth_mac1 = "/soc@0/bus@30000000/efuse@30350000/mac-address@90";
		eth_mac2 = "/soc@0/bus@30000000/efuse@30350000/mac-address@96";
		tmu_calib = "/soc@0/bus@30000000/efuse@30350000/calib@264";
		anatop = "/soc@0/bus@30000000/clock-controller@30360000";
		snvs = "/soc@0/bus@30000000/snvs@30370000";
		snvs_rtc = "/soc@0/bus@30000000/snvs@30370000/snvs-rtc-lp";
		snvs_pwrkey = "/soc@0/bus@30000000/snvs@30370000/snvs-powerkey";
		snvs_lpgpr = "/soc@0/bus@30000000/snvs@30370000/snvs-lpgpr";
		clk = "/soc@0/bus@30000000/clock-controller@30380000";
		src = "/soc@0/bus@30000000/reset-controller@30390000";
		gpc = "/soc@0/bus@30000000/gpc@303a0000";
		pgc_mipi_phy1 = "/soc@0/bus@30000000/gpc@303a0000/pgc/power-domain@0";
		pgc_pcie_phy = "/soc@0/bus@30000000/gpc@303a0000/pgc/power-domain@1";
		pgc_usb1_phy = "/soc@0/bus@30000000/gpc@303a0000/pgc/power-domain@2";
		pgc_usb2_phy = "/soc@0/bus@30000000/gpc@303a0000/pgc/power-domain@3";
		pgc_audio = "/soc@0/bus@30000000/gpc@303a0000/pgc/power-domain@5";
		pgc_gpu2d = "/soc@0/bus@30000000/gpc@303a0000/pgc/power-domain@6";
		pgc_gpumix = "/soc@0/bus@30000000/gpc@303a0000/pgc/power-domain@7";
		pgc_gpu3d = "/soc@0/bus@30000000/gpc@303a0000/pgc/power-domain@9";
		pgc_mediamix = "/soc@0/bus@30000000/gpc@303a0000/pgc/power-domain@10";
		pgc_hdmimix = "/soc@0/bus@30000000/gpc@303a0000/pgc/power-domains@14";
		pgc_hdmi_phy = "/soc@0/bus@30000000/gpc@303a0000/pgc/power-domains@15";
		pgc_mipi_phy2 = "/soc@0/bus@30000000/gpc@303a0000/pgc/power-domain@16";
		pgc_hsiomix = "/soc@0/bus@30000000/gpc@303a0000/pgc/power-domain@17";
		pgc_ispdwp = "/soc@0/bus@30000000/gpc@303a0000/pgc/power-domain@18";
		pgc_vpumix = "/soc@0/bus@30000000/gpc@303a0000/pgc/power-domain@19";
		pgc_vpu_g1 = "/soc@0/bus@30000000/gpc@303a0000/pgc/power-domain@20";
		pgc_vpu_g2 = "/soc@0/bus@30000000/gpc@303a0000/pgc/power-domain@21";
		pgc_vpu_vc8000e = "/soc@0/bus@30000000/gpc@303a0000/pgc/power-domain@22";
		pgc_mlmix = "/soc@0/bus@30000000/gpc@303a0000/pgc/power-domain@24";
		aips2 = "/soc@0/bus@30400000";
		pwm1 = "/soc@0/bus@30400000/pwm@30660000";
		pwm2 = "/soc@0/bus@30400000/pwm@30670000";
		pwm3 = "/soc@0/bus@30400000/pwm@30680000";
		pwm4 = "/soc@0/bus@30400000/pwm@30690000";
		system_counter = "/soc@0/bus@30400000/timer@306a0000";
		gpt6 = "/soc@0/bus@30400000/timer@306e0000";
		gpt5 = "/soc@0/bus@30400000/timer@306f0000";
		gpt4 = "/soc@0/bus@30400000/timer@30700000";
		aips3 = "/soc@0/bus@30800000";
		ecspi1 = "/soc@0/bus@30800000/spba-bus@30800000/spi@30820000";
		ecspi2 = "/soc@0/bus@30800000/spba-bus@30800000/spi@30830000";
		ecspi3 = "/soc@0/bus@30800000/spba-bus@30800000/spi@30840000";
		uart1 = "/soc@0/bus@30800000/spba-bus@30800000/serial@30860000";
		uart3 = "/soc@0/bus@30800000/spba-bus@30800000/serial@30880000";
		uart2 = "/soc@0/bus@30800000/spba-bus@30800000/serial@30890000";
		flexcan1 = "/soc@0/bus@30800000/spba-bus@30800000/can@308c0000";
		flexcan2 = "/soc@0/bus@30800000/spba-bus@30800000/can@308d0000";
		crypto = "/soc@0/bus@30800000/crypto@30900000";
		sec_jr0 = "/soc@0/bus@30800000/crypto@30900000/jr@1000";
		sec_jr1 = "/soc@0/bus@30800000/crypto@30900000/jr@2000";
		sec_jr2 = "/soc@0/bus@30800000/crypto@30900000/jr@3000";
		i2c1 = "/soc@0/bus@30800000/i2c@30a20000";
		buck1 = "/soc@0/bus@30800000/i2c@30a20000/pmic@25/regulators/BUCK1";
		buck2 = "/soc@0/bus@30800000/i2c@30a20000/pmic@25/regulators/BUCK2";
		buck4 = "/soc@0/bus@30800000/i2c@30a20000/pmic@25/regulators/BUCK4";
		buck5 = "/soc@0/bus@30800000/i2c@30a20000/pmic@25/regulators/BUCK5";
		buck6 = "/soc@0/bus@30800000/i2c@30a20000/pmic@25/regulators/BUCK6";
		ldo1 = "/soc@0/bus@30800000/i2c@30a20000/pmic@25/regulators/LDO1";
		ldo2 = "/soc@0/bus@30800000/i2c@30a20000/pmic@25/regulators/LDO2";
		ldo3 = "/soc@0/bus@30800000/i2c@30a20000/pmic@25/regulators/LDO3";
		ldo4 = "/soc@0/bus@30800000/i2c@30a20000/pmic@25/regulators/LDO4";
		ldo5 = "/soc@0/bus@30800000/i2c@30a20000/pmic@25/regulators/LDO5";
		i2c2 = "/soc@0/bus@30800000/i2c@30a30000";
		i2c3 = "/soc@0/bus@30800000/i2c@30a40000";
		i2c4 = "/soc@0/bus@30800000/i2c@30a50000";
		uart4 = "/soc@0/bus@30800000/serial@30a60000";
		mu = "/soc@0/bus@30800000/mailbox@30aa0000";
		mu2 = "/soc@0/bus@30800000/mailbox@30e60000";
		i2c5 = "/soc@0/bus@30800000/i2c@30ad0000";
		i2c6 = "/soc@0/bus@30800000/i2c@30ae0000";
		usdhc1 = "/soc@0/bus@30800000/mmc@30b40000";
		usdhc2 = "/soc@0/bus@30800000/mmc@30b50000";
		usdhc3 = "/soc@0/bus@30800000/mmc@30b60000";
		flexspi = "/soc@0/bus@30800000/spi@30bb0000";
		sdma1 = "/soc@0/bus@30800000/dma-controller@30bd0000";
		fec = "/soc@0/bus@30800000/ethernet@30be0000";
		eqos = "/soc@0/bus@30800000/ethernet@30bf0000";
		ethphy0 = "/soc@0/bus@30800000/ethernet@30bf0000/mdio/ethernet-phy@0";
		aips5 = "/soc@0/bus@30c00000";
		sai1 = "/soc@0/bus@30c00000/spba-bus@30c00000/sai@30c10000";
		sai2 = "/soc@0/bus@30c00000/spba-bus@30c00000/sai@30c20000";
		sai3 = "/soc@0/bus@30c00000/spba-bus@30c00000/sai@30c30000";
		sai5 = "/soc@0/bus@30c00000/spba-bus@30c00000/sai@30c50000";
		sai6 = "/soc@0/bus@30c00000/spba-bus@30c00000/sai@30c60000";
		sai7 = "/soc@0/bus@30c00000/spba-bus@30c00000/sai@30c80000";
		sdma3 = "/soc@0/bus@30c00000/dma-controller@30e00000";
		sdma2 = "/soc@0/bus@30c00000/dma-controller@30e10000";
		audio_blk_ctrl = "/soc@0/bus@30c00000/clock-controller@30e20000";
		noc = "/soc@0/interconnect@32700000";
		noc_opp_table = "/soc@0/interconnect@32700000/opp-table";
		aips4 = "/soc@0/bus@32c00000";
		isi_0 = "/soc@0/bus@32c00000/isi@32e00000";
		isi_in_0 = "/soc@0/bus@32c00000/isi@32e00000/ports/port@0/endpoint";
		isi_in_1 = "/soc@0/bus@32c00000/isi@32e00000/ports/port@1/endpoint";
		isp_0 = "/soc@0/bus@32c00000/isp@32e10000";
		isp_1 = "/soc@0/bus@32c00000/isp@32e20000";
		dewarp = "/soc@0/bus@32c00000/dwe@32e30000";
		mipi_csi_0 = "/soc@0/bus@32c00000/csi@32e40000";
		mipi_csi_0_out = "/soc@0/bus@32c00000/csi@32e40000/ports/port@1/endpoint";
		mipi_csi_1 = "/soc@0/bus@32c00000/csi@32e50000";
		mipi_csi_1_out = "/soc@0/bus@32c00000/csi@32e50000/ports/port@1/endpoint";
		mipi_dsi = "/soc@0/bus@32c00000/dsi@32e60000";
		dsim_from_lcdif1 = "/soc@0/bus@32c00000/dsi@32e60000/ports/port@0/endpoint";
		lcdif1 = "/soc@0/bus@32c00000/display-controller@32e80000";
		lcdif1_to_dsim = "/soc@0/bus@32c00000/display-controller@32e80000/port/endpoint";
		lcdif2 = "/soc@0/bus@32c00000/display-controller@32e90000";
		lcdif2_to_ldb = "/soc@0/bus@32c00000/display-controller@32e90000/port/endpoint";
		media_blk_ctrl = "/soc@0/bus@32c00000/blk-ctrl@32ec0000";
		lvds_bridge = "/soc@0/bus@32c00000/blk-ctrl@32ec0000/bridge@5c";
		ldb_from_lcdif2 = "/soc@0/bus@32c00000/blk-ctrl@32ec0000/bridge@5c/ports/port@0/endpoint";
		ldb_lvds_ch0 = "/soc@0/bus@32c00000/blk-ctrl@32ec0000/bridge@5c/ports/port@1/endpoint";
		ldb_lvds_ch1 = "/soc@0/bus@32c00000/blk-ctrl@32ec0000/bridge@5c/ports/port@2/endpoint";
		pcie_phy = "/soc@0/bus@32c00000/pcie-phy@32f00000";
		hsio_blk_ctrl = "/soc@0/bus@32c00000/blk-ctrl@32f10000";
		hdmi_blk_ctrl = "/soc@0/bus@32c00000/blk-ctrl@32fc0000";
		irqsteer_hdmi = "/soc@0/bus@32c00000/interrupt-controller@32fc2000";
		hdmi_pvi = "/soc@0/bus@32c00000/display-bridge@32fc4000";
		pvi_from_lcdif3 = "/soc@0/bus@32c00000/display-bridge@32fc4000/ports/port@0/endpoint";
		pvi_to_hdmi_tx = "/soc@0/bus@32c00000/display-bridge@32fc4000/ports/port@1/endpoint";
		lcdif3 = "/soc@0/bus@32c00000/display-controller@32fc6000";
		lcdif3_to_pvi = "/soc@0/bus@32c00000/display-controller@32fc6000/port/endpoint";
		hdmi_tx = "/soc@0/bus@32c00000/hdmi@32fd8000";
		hdmi_tx_from_pvi = "/soc@0/bus@32c00000/hdmi@32fd8000/port/endpoint";
		hdmi_tx_phy = "/soc@0/bus@32c00000/phy@32fdff00";
		pcie = "/soc@0/pcie@33800000";
		pcie_ep = "/soc@0/pcie-ep@33800000";
		gpu3d = "/soc@0/gpu@38000000";
		gpu2d = "/soc@0/gpu@38008000";
		vpu_g1 = "/soc@0/video-codec@38300000";
		vpu_g2 = "/soc@0/video-codec@38310000";
		vpumix_blk_ctrl = "/soc@0/blk-ctrl@38330000";
		gic = "/soc@0/interrupt-controller@38800000";
		edacmc = "/soc@0/memory-controller@3d400000";
		usb3_phy0 = "/soc@0/usb-phy@381f0040";
		usb3_0 = "/soc@0/usb@32f10100";
		usb_dwc3_0 = "/soc@0/usb@32f10100/usb@38100000";
		usb3_phy1 = "/soc@0/usb-phy@382f0040";
		usb3_1 = "/soc@0/usb@32f10108";
		usb_dwc3_1 = "/soc@0/usb@32f10108/usb@38200000";
		usb_hub_2_x = "/soc@0/usb@32f10108/usb@38200000/hub@1";
		usb_hub_3_x = "/soc@0/usb@32f10108/usb@38200000/hub@2";
		dsp = "/soc@0/dsp@3b6e8000";
		reg_usdhc2_vmmc = "/regulator-usdhc2";
		reg_usb_hub = "/regulator-usb-hub";
	};
};
